AUTOSAR XML (schema 4-0-3)
package /Nexteer/CDD_NvMProxy_swc/ComponentTypes
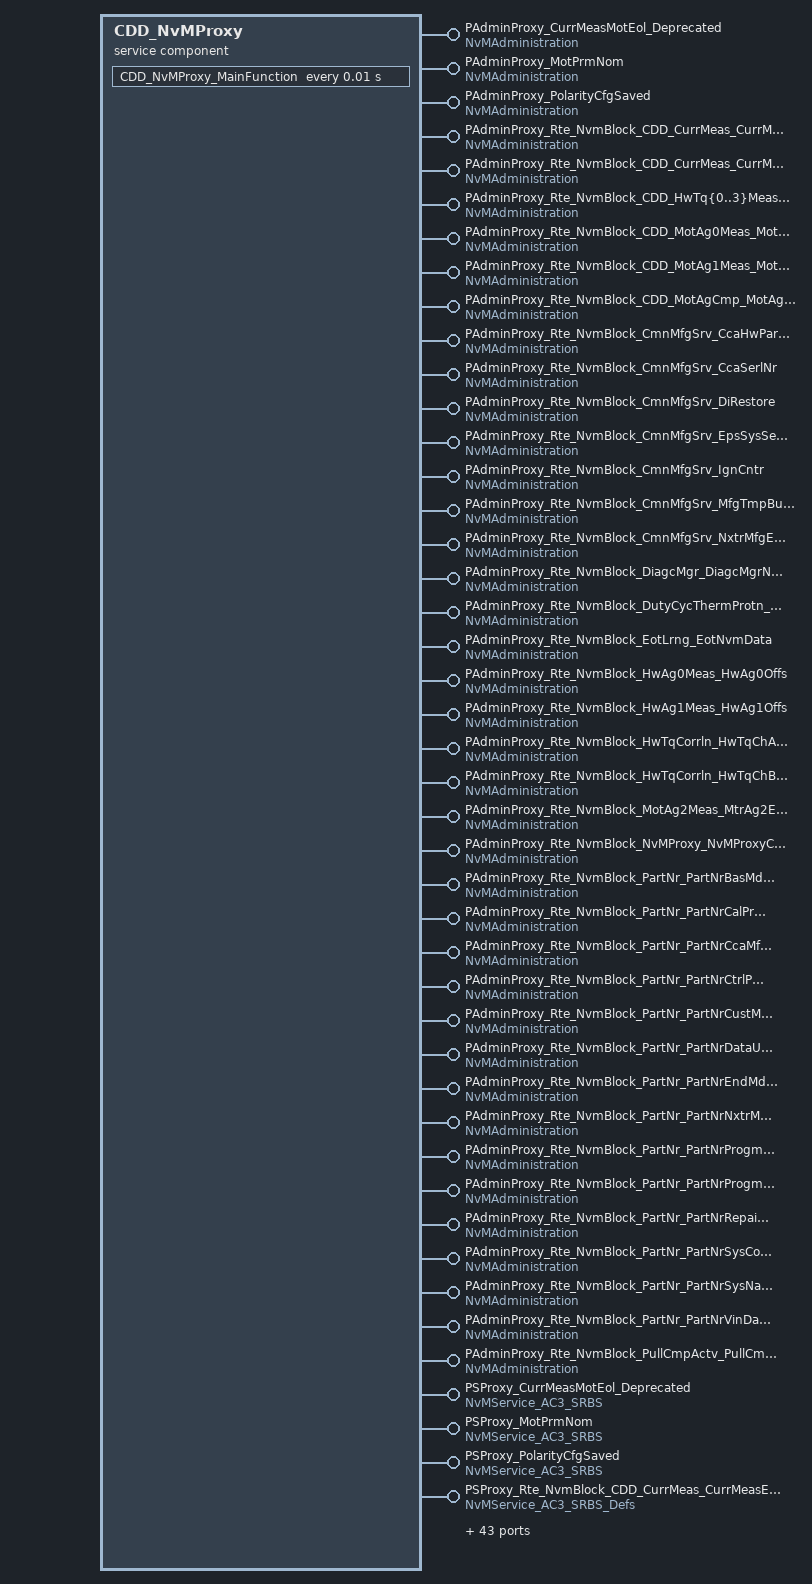
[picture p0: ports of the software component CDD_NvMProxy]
  service sw component type CDD_NvMProxy
    94 x provide port:
      PAdminProxy_CurrMeasMotEol_Deprecated: server-com-spec{operation=SetBlockProtection, queue-length=1}, provided-interface=NvMAdministration
      PAdminProxy_MotPrmNom: server-com-spec{operation=SetBlockProtection, queue-length=1}, provided-interface=NvMAdministration
      PAdminProxy_PolarityCfgSaved: server-com-spec{operation=SetBlockProtection, queue-length=1}, provided-interface=NvMAdministration
      PAdminProxy_Rte_NvmBlock_CDD_CurrMeas_CurrMeasEolGainCalSet: server-com-spec{operation=SetBlockProtection, queue-length=1}, provided-interface=NvMAdministration
      PAdminProxy_Rte_NvmBlock_CDD_CurrMeas_CurrMeasEolOffsCalSet: server-com-spec{operation=SetBlockProtection, queue-length=1}, provided-interface=NvMAdministration
      PAdminProxy_Rte_NvmBlock_CDD_HwTq{0..3}Meas_HwTq{0..3}Offs: server-com-spec{operation=SetBlockProtection, queue-length=1}, provided-interface=NvMAdministration
      PAdminProxy_Rte_NvmBlock_CDD_MotAg0Meas_MotAg0CoeffTbl: server-com-spec{operation=SetBlockProtection, queue-length=1}, provided-interface=NvMAdministration
      PAdminProxy_Rte_NvmBlock_CDD_MotAg1Meas_MotAg1CoeffTbl: server-com-spec{operation=SetBlockProtection, queue-length=1}, provided-interface=NvMAdministration
      PAdminProxy_Rte_NvmBlock_CDD_MotAgCmp_MotAgCmpMotAgBackEmf: server-com-spec{operation=SetBlockProtection, queue-length=1}, provided-interface=NvMAdministration
      PAdminProxy_Rte_NvmBlock_CmnMfgSrv_CcaHwPartNr: server-com-spec{operation=SetBlockProtection, queue-length=1}, provided-interface=NvMAdministration
      PAdminProxy_Rte_NvmBlock_CmnMfgSrv_CcaSerlNr: server-com-spec{operation=SetBlockProtection, queue-length=1}, provided-interface=NvMAdministration
      PAdminProxy_Rte_NvmBlock_CmnMfgSrv_DiRestore: server-com-spec{operation=SetBlockProtection, queue-length=1}, provided-interface=NvMAdministration
      PAdminProxy_Rte_NvmBlock_CmnMfgSrv_EpsSysSerlNr: server-com-spec{operation=SetBlockProtection, queue-length=1}, provided-interface=NvMAdministration
      PAdminProxy_Rte_NvmBlock_CmnMfgSrv_IgnCntr: server-com-spec{operation=SetBlockProtection, queue-length=1}, provided-interface=NvMAdministration
      PAdminProxy_Rte_NvmBlock_CmnMfgSrv_MfgTmpBuf{0..4}: server-com-spec{operation=SetBlockProtection, queue-length=1}, provided-interface=NvMAdministration
      PAdminProxy_Rte_NvmBlock_CmnMfgSrv_NxtrMfgEnaCntr: server-com-spec{operation=SetBlockProtection, queue-length=1}, provided-interface=NvMAdministration
      PAdminProxy_Rte_NvmBlock_DiagcMgr_DiagcMgrNtcFltAry: server-com-spec{operation=SetBlockProtection, queue-length=1}, provided-interface=NvMAdministration
      PAdminProxy_Rte_NvmBlock_DutyCycThermProtn_FilStVal: server-com-spec{operation=SetBlockProtection, queue-length=1}, provided-interface=NvMAdministration
      PAdminProxy_Rte_NvmBlock_EotLrng_EotNvmData: server-com-spec{operation=SetBlockProtection, queue-length=1}, provided-interface=NvMAdministration
      PAdminProxy_Rte_NvmBlock_HwAg0Meas_HwAg0Offs: server-com-spec{operation=SetBlockProtection, queue-length=1}, provided-interface=NvMAdministration
      PAdminProxy_Rte_NvmBlock_HwAg1Meas_HwAg1Offs: server-com-spec{operation=SetBlockProtection, queue-length=1}, provided-interface=NvMAdministration
      PAdminProxy_Rte_NvmBlock_HwTqCorrln_HwTqChACmnModCmpLpFilSt: server-com-spec{operation=SetBlockProtection, queue-length=1}, provided-interface=NvMAdministration
      PAdminProxy_Rte_NvmBlock_HwTqCorrln_HwTqChBCmnModCmpLpFilSt: server-com-spec{operation=SetBlockProtection, queue-length=1}, provided-interface=NvMAdministration
      PAdminProxy_Rte_NvmBlock_MotAg2Meas_MtrAg2EolPrm: server-com-spec{operation=SetBlockProtection, queue-length=1}, provided-interface=NvMAdministration
      PAdminProxy_Rte_NvmBlock_NvMProxy_NvMProxyClsChkBlk: server-com-spec{operation=SetBlockProtection, queue-length=1}, provided-interface=NvMAdministration
      PAdminProxy_Rte_NvmBlock_PartNr_PartNrBasMdlPartNr: server-com-spec{operation=SetBlockProtection, queue-length=1}, provided-interface=NvMAdministration
      PAdminProxy_Rte_NvmBlock_PartNr_PartNrCalProgdSts: server-com-spec{operation=SetBlockProtection, queue-length=1}, provided-interface=NvMAdministration
      PAdminProxy_Rte_NvmBlock_PartNr_PartNrCcaMfgTrakg: server-com-spec{operation=SetBlockProtection, queue-length=1}, provided-interface=NvMAdministration
      PAdminProxy_Rte_NvmBlock_PartNr_PartNrCtrlPidSeedKey: server-com-spec{operation=SetBlockProtection, queue-length=1}, provided-interface=NvMAdministration
      PAdminProxy_Rte_NvmBlock_PartNr_PartNrCustMfgEnaCntr: server-com-spec{operation=SetBlockProtection, queue-length=1}, provided-interface=NvMAdministration
      PAdminProxy_Rte_NvmBlock_PartNr_PartNrDataUniversalNrSysId: server-com-spec{operation=SetBlockProtection, queue-length=1}, provided-interface=NvMAdministration
      PAdminProxy_Rte_NvmBlock_PartNr_PartNrEndMdlPartNr: server-com-spec{operation=SetBlockProtection, queue-length=1}, provided-interface=NvMAdministration
      PAdminProxy_Rte_NvmBlock_PartNr_PartNrNxtrMfgTrakg: server-com-spec{operation=SetBlockProtection, queue-length=1}, provided-interface=NvMAdministration
      PAdminProxy_Rte_NvmBlock_PartNr_PartNrProgmDate: server-com-spec{operation=SetBlockProtection, queue-length=1}, provided-interface=NvMAdministration
      PAdminProxy_Rte_NvmBlock_PartNr_PartNrProgmSessionSeedKey: server-com-spec{operation=SetBlockProtection, queue-length=1}, provided-interface=NvMAdministration
      PAdminProxy_Rte_NvmBlock_PartNr_PartNrRepairShopCod: server-com-spec{operation=SetBlockProtection, queue-length=1}, provided-interface=NvMAdministration
      PAdminProxy_Rte_NvmBlock_PartNr_PartNrSysCodVersNr: server-com-spec{operation=SetBlockProtection, queue-length=1}, provided-interface=NvMAdministration
      PAdminProxy_Rte_NvmBlock_PartNr_PartNrSysName: server-com-spec{operation=SetBlockProtection, queue-length=1}, provided-interface=NvMAdministration
      PAdminProxy_Rte_NvmBlock_PartNr_PartNrVinData: server-com-spec{operation=SetBlockProtection, queue-length=1}, provided-interface=NvMAdministration
      PAdminProxy_Rte_NvmBlock_PullCmpActv_PullCmpLongTerm: server-com-spec{operation=SetBlockProtection, queue-length=1}, provided-interface=NvMAdministration
      PSProxy_CurrMeasMotEol_Deprecated: provided-interface=NvMService_AC3_SRBS
        provided-com-specs:
          operation=EraseBlock, queue-length=1
          operation=GetErrorStatus, queue-length=1
          operation=InvalidateNvBlock, queue-length=1
          operation=ReadBlock, queue-length=1
          operation=SetRamBlockStatus, queue-length=1
          operation=WriteBlock, queue-length=1
      PSProxy_MotPrmNom: provided-interface=NvMService_AC3_SRBS
        provided-com-specs:
          operation=EraseBlock, queue-length=1
          operation=GetErrorStatus, queue-length=1
          operation=InvalidateNvBlock, queue-length=1
          operation=ReadBlock, queue-length=1
          operation=SetRamBlockStatus, queue-length=1
          operation=WriteBlock, queue-length=1
      PSProxy_PolarityCfgSaved: provided-interface=NvMService_AC3_SRBS
        provided-com-specs:
          operation=EraseBlock, queue-length=1
          operation=GetErrorStatus, queue-length=1
          operation=InvalidateNvBlock, queue-length=1
          operation=ReadBlock, queue-length=1
          operation=SetRamBlockStatus, queue-length=1
          operation=WriteBlock, queue-length=1
      PSProxy_Rte_NvmBlock_CDD_CurrMeas_CurrMeasEolGainCalSet: provided-interface=NvMService_AC3_SRBS_Defs
        provided-com-specs:
          operation=EraseBlock, queue-length=1
          operation=GetErrorStatus, queue-length=1
          operation=InvalidateNvBlock, queue-length=1
          operation=ReadBlock, queue-length=1
          operation=RestoreBlockDefaults, queue-length=1
          operation=SetRamBlockStatus, queue-length=1
          operation=WriteBlock, queue-length=1
      PSProxy_Rte_NvmBlock_CDD_CurrMeas_CurrMeasEolOffsCalSet: provided-interface=NvMService_AC3_SRBS_Defs
        provided-com-specs:
          operation=EraseBlock, queue-length=1
          operation=GetErrorStatus, queue-length=1
          operation=InvalidateNvBlock, queue-length=1
          operation=ReadBlock, queue-length=1
          operation=RestoreBlockDefaults, queue-length=1
          operation=SetRamBlockStatus, queue-length=1
          operation=WriteBlock, queue-length=1
      PSProxy_Rte_NvmBlock_CDD_HwTq0Meas_HwTq0Offs: provided-interface=NvMService_AC3_SRBS_Defs
        provided-com-specs:
          operation=EraseBlock, queue-length=1
          operation=GetErrorStatus, queue-length=1
          operation=InvalidateNvBlock, queue-length=1
          operation=ReadBlock, queue-length=1
          operation=RestoreBlockDefaults, queue-length=1
          operation=SetRamBlockStatus, queue-length=1
          operation=WriteBlock, queue-length=1
      PSProxy_Rte_NvmBlock_CDD_HwTq1Meas_HwTq1Offs: provided-interface=NvMService_AC3_SRBS_Defs
        provided-com-specs:
          operation=EraseBlock, queue-length=1
          operation=GetErrorStatus, queue-length=1
          operation=InvalidateNvBlock, queue-length=1
          operation=ReadBlock, queue-length=1
          operation=RestoreBlockDefaults, queue-length=1
          operation=SetRamBlockStatus, queue-length=1
          operation=WriteBlock, queue-length=1
      PSProxy_Rte_NvmBlock_CDD_HwTq2Meas_HwTq2Offs: provided-interface=NvMService_AC3_SRBS_Defs
        provided-com-specs:
          operation=EraseBlock, queue-length=1
          operation=GetErrorStatus, queue-length=1
          operation=InvalidateNvBlock, queue-length=1
          operation=ReadBlock, queue-length=1
          operation=RestoreBlockDefaults, queue-length=1
          operation=SetRamBlockStatus, queue-length=1
          operation=WriteBlock, queue-length=1
      PSProxy_Rte_NvmBlock_CDD_HwTq3Meas_HwTq3Offs: provided-interface=NvMService_AC3_SRBS_Defs
        provided-com-specs:
          operation=EraseBlock, queue-length=1
          operation=GetErrorStatus, queue-length=1
          operation=InvalidateNvBlock, queue-length=1
          operation=ReadBlock, queue-length=1
          operation=RestoreBlockDefaults, queue-length=1
          operation=SetRamBlockStatus, queue-length=1
          operation=WriteBlock, queue-length=1
      PSProxy_Rte_NvmBlock_CDD_MotAg0Meas_MotAg0CoeffTbl: provided-interface=NvMService_AC3_SRBS_Defs
        provided-com-specs:
          operation=EraseBlock, queue-length=1
          operation=GetErrorStatus, queue-length=1
          operation=InvalidateNvBlock, queue-length=1
          operation=ReadBlock, queue-length=1
          operation=RestoreBlockDefaults, queue-length=1
          operation=SetRamBlockStatus, queue-length=1
          operation=WriteBlock, queue-length=1
      PSProxy_Rte_NvmBlock_CDD_MotAg1Meas_MotAg1CoeffTbl: provided-interface=NvMService_AC3_SRBS_Defs
        provided-com-specs:
          operation=EraseBlock, queue-length=1
          operation=GetErrorStatus, queue-length=1
          operation=InvalidateNvBlock, queue-length=1
          operation=ReadBlock, queue-length=1
          operation=RestoreBlockDefaults, queue-length=1
          operation=SetRamBlockStatus, queue-length=1
          operation=WriteBlock, queue-length=1
      PSProxy_Rte_NvmBlock_CDD_MotAgCmp_MotAgCmpMotAgBackEmf: provided-interface=NvMService_AC3_SRBS_Defs
        provided-com-specs:
          operation=EraseBlock, queue-length=1
          operation=GetErrorStatus, queue-length=1
          operation=InvalidateNvBlock, queue-length=1
          operation=ReadBlock, queue-length=1
          operation=RestoreBlockDefaults, queue-length=1
          operation=SetRamBlockStatus, queue-length=1
          operation=WriteBlock, queue-length=1
      PSProxy_Rte_NvmBlock_CmnMfgSrv_CcaHwPartNr: provided-interface=NvMService_AC3_SRBS
        provided-com-specs:
          operation=EraseBlock, queue-length=1
          operation=GetErrorStatus, queue-length=1
          operation=InvalidateNvBlock, queue-length=1
          operation=ReadBlock, queue-length=1
          operation=SetRamBlockStatus, queue-length=1
          operation=WriteBlock, queue-length=1
      PSProxy_Rte_NvmBlock_CmnMfgSrv_CcaSerlNr: provided-interface=NvMService_AC3_SRBS
        provided-com-specs:
          operation=EraseBlock, queue-length=1
          operation=GetErrorStatus, queue-length=1
          operation=InvalidateNvBlock, queue-length=1
          operation=ReadBlock, queue-length=1
          operation=SetRamBlockStatus, queue-length=1
          operation=WriteBlock, queue-length=1
      PSProxy_Rte_NvmBlock_CmnMfgSrv_DiRestore: provided-interface=NvMService_AC3_SRBS
        provided-com-specs:
          operation=EraseBlock, queue-length=1
          operation=GetErrorStatus, queue-length=1
          operation=InvalidateNvBlock, queue-length=1
          operation=ReadBlock, queue-length=1
          operation=SetRamBlockStatus, queue-length=1
          operation=WriteBlock, queue-length=1
      PSProxy_Rte_NvmBlock_CmnMfgSrv_EpsSysSerlNr: provided-interface=NvMService_AC3_SRBS
        provided-com-specs:
          operation=EraseBlock, queue-length=1
          operation=GetErrorStatus, queue-length=1
          operation=InvalidateNvBlock, queue-length=1
          operation=ReadBlock, queue-length=1
          operation=SetRamBlockStatus, queue-length=1
          operation=WriteBlock, queue-length=1
      PSProxy_Rte_NvmBlock_CmnMfgSrv_IgnCntr: provided-interface=NvMService_AC3_SRBS_Defs
        provided-com-specs:
          operation=EraseBlock, queue-length=1
          operation=GetErrorStatus, queue-length=1
          operation=InvalidateNvBlock, queue-length=1
          operation=ReadBlock, queue-length=1
          operation=RestoreBlockDefaults, queue-length=1
          operation=SetRamBlockStatus, queue-length=1
          operation=WriteBlock, queue-length=1
      PSProxy_Rte_NvmBlock_CmnMfgSrv_MfgTmpBuf0: provided-interface=NvMService_AC3_SRBS
        provided-com-specs:
          operation=EraseBlock, queue-length=1
          operation=GetErrorStatus, queue-length=1
          operation=InvalidateNvBlock, queue-length=1
          operation=ReadBlock, queue-length=1
          operation=SetRamBlockStatus, queue-length=1
          operation=WriteBlock, queue-length=1
      PSProxy_Rte_NvmBlock_CmnMfgSrv_MfgTmpBuf1: provided-interface=NvMService_AC3_SRBS
        provided-com-specs:
          operation=EraseBlock, queue-length=1
          operation=GetErrorStatus, queue-length=1
          operation=InvalidateNvBlock, queue-length=1
          operation=ReadBlock, queue-length=1
          operation=SetRamBlockStatus, queue-length=1
          operation=WriteBlock, queue-length=1
      PSProxy_Rte_NvmBlock_CmnMfgSrv_MfgTmpBuf2: provided-interface=NvMService_AC3_SRBS
        provided-com-specs:
          operation=EraseBlock, queue-length=1
          operation=GetErrorStatus, queue-length=1
          operation=InvalidateNvBlock, queue-length=1
          operation=ReadBlock, queue-length=1
          operation=SetRamBlockStatus, queue-length=1
          operation=WriteBlock, queue-length=1
      PSProxy_Rte_NvmBlock_CmnMfgSrv_MfgTmpBuf3: provided-interface=NvMService_AC3_SRBS
        provided-com-specs:
          operation=EraseBlock, queue-length=1
          operation=GetErrorStatus, queue-length=1
          operation=InvalidateNvBlock, queue-length=1
          operation=ReadBlock, queue-length=1
          operation=SetRamBlockStatus, queue-length=1
          operation=WriteBlock, queue-length=1
      PSProxy_Rte_NvmBlock_CmnMfgSrv_MfgTmpBuf4: provided-interface=NvMService_AC3_SRBS
        provided-com-specs:
          operation=EraseBlock, queue-length=1
          operation=GetErrorStatus, queue-length=1
          operation=InvalidateNvBlock, queue-length=1
          operation=ReadBlock, queue-length=1
          operation=SetRamBlockStatus, queue-length=1
          operation=WriteBlock, queue-length=1
      PSProxy_Rte_NvmBlock_CmnMfgSrv_NxtrMfgEnaCntr: provided-interface=NvMService_AC3_SRBS_Defs
        provided-com-specs:
          operation=EraseBlock, queue-length=1
          operation=GetErrorStatus, queue-length=1
          operation=InvalidateNvBlock, queue-length=1
          operation=ReadBlock, queue-length=1
          operation=RestoreBlockDefaults, queue-length=1
          operation=SetRamBlockStatus, queue-length=1
          operation=WriteBlock, queue-length=1
      PSProxy_Rte_NvmBlock_DiagcMgr_DiagcMgrNtcFltAry: provided-interface=NvMService_AC3_SRBS
        provided-com-specs:
          operation=EraseBlock, queue-length=1
          operation=GetErrorStatus, queue-length=1
          operation=InvalidateNvBlock, queue-length=1
          operation=ReadBlock, queue-length=1
          operation=SetRamBlockStatus, queue-length=1
          operation=WriteBlock, queue-length=1
      PSProxy_Rte_NvmBlock_DutyCycThermProtn_FilStVal: provided-interface=NvMService_AC3_SRBS_Defs
        provided-com-specs:
          operation=EraseBlock, queue-length=1
          operation=GetErrorStatus, queue-length=1
          operation=InvalidateNvBlock, queue-length=1
          operation=ReadBlock, queue-length=1
          operation=RestoreBlockDefaults, queue-length=1
          operation=SetRamBlockStatus, queue-length=1
          operation=WriteBlock, queue-length=1
      PSProxy_Rte_NvmBlock_EotLrng_EotNvmData: provided-interface=NvMService_AC3_SRBS_Defs
        provided-com-specs:
          operation=EraseBlock, queue-length=1
          operation=GetErrorStatus, queue-length=1
          operation=InvalidateNvBlock, queue-length=1
          operation=ReadBlock, queue-length=1
          operation=RestoreBlockDefaults, queue-length=1
          operation=SetRamBlockStatus, queue-length=1
          operation=WriteBlock, queue-length=1
      PSProxy_Rte_NvmBlock_HwAg0Meas_HwAg0Offs: provided-interface=NvMService_AC3_SRBS_Defs
        provided-com-specs:
          operation=EraseBlock, queue-length=1
          operation=GetErrorStatus, queue-length=1
          operation=InvalidateNvBlock, queue-length=1
          operation=ReadBlock, queue-length=1
          operation=RestoreBlockDefaults, queue-length=1
          operation=SetRamBlockStatus, queue-length=1
          operation=WriteBlock, queue-length=1
      PSProxy_Rte_NvmBlock_HwAg1Meas_HwAg1Offs: provided-interface=NvMService_AC3_SRBS_Defs
        provided-com-specs:
          operation=EraseBlock, queue-length=1
          operation=GetErrorStatus, queue-length=1
          operation=InvalidateNvBlock, queue-length=1
          operation=ReadBlock, queue-length=1
          operation=RestoreBlockDefaults, queue-length=1
          operation=SetRamBlockStatus, queue-length=1
          operation=WriteBlock, queue-length=1
      PSProxy_Rte_NvmBlock_HwTqCorrln_HwTqChACmnModCmpLpFilSt: provided-interface=NvMService_AC3_SRBS_Defs
        provided-com-specs:
          operation=EraseBlock, queue-length=1
          operation=GetErrorStatus, queue-length=1
          operation=InvalidateNvBlock, queue-length=1
          operation=ReadBlock, queue-length=1
          operation=RestoreBlockDefaults, queue-length=1
          operation=SetRamBlockStatus, queue-length=1
          operation=WriteBlock, queue-length=1
      PSProxy_Rte_NvmBlock_HwTqCorrln_HwTqChBCmnModCmpLpFilSt: provided-interface=NvMService_AC3_SRBS_Defs
        provided-com-specs:
          operation=EraseBlock, queue-length=1
          operation=GetErrorStatus, queue-length=1
          operation=InvalidateNvBlock, queue-length=1
          operation=ReadBlock, queue-length=1
          operation=RestoreBlockDefaults, queue-length=1
          operation=SetRamBlockStatus, queue-length=1
          operation=WriteBlock, queue-length=1
      PSProxy_Rte_NvmBlock_MotAg2Meas_MtrAg2EolPrm: provided-interface=NvMService_AC3_SRBS_Defs
        provided-com-specs:
          operation=EraseBlock, queue-length=1
          operation=GetErrorStatus, queue-length=1
          operation=InvalidateNvBlock, queue-length=1
          operation=ReadBlock, queue-length=1
          operation=RestoreBlockDefaults, queue-length=1
          operation=SetRamBlockStatus, queue-length=1
          operation=WriteBlock, queue-length=1
      PSProxy_Rte_NvmBlock_NvMProxy_NvMProxyClsChkBlk: provided-interface=NvMService_AC3_SRBS
        provided-com-specs:
          operation=EraseBlock, queue-length=1
          operation=GetErrorStatus, queue-length=1
          operation=InvalidateNvBlock, queue-length=1
          operation=ReadBlock, queue-length=1
          operation=SetRamBlockStatus, queue-length=1
          operation=WriteBlock, queue-length=1
      PSProxy_Rte_NvmBlock_PartNr_PartNrBasMdlPartNr: provided-interface=NvMService_AC3_SRBS_Defs
        provided-com-specs:
          operation=EraseBlock, queue-length=1
          operation=GetErrorStatus, queue-length=1
          operation=InvalidateNvBlock, queue-length=1
          operation=ReadBlock, queue-length=1
          operation=RestoreBlockDefaults, queue-length=1
          operation=SetRamBlockStatus, queue-length=1
          operation=WriteBlock, queue-length=1
      PSProxy_Rte_NvmBlock_PartNr_PartNrCalProgdSts: provided-interface=NvMService_AC3_SRBS_Defs
        provided-com-specs:
          operation=EraseBlock, queue-length=1
          operation=GetErrorStatus, queue-length=1
          operation=InvalidateNvBlock, queue-length=1
          operation=ReadBlock, queue-length=1
          operation=RestoreBlockDefaults, queue-length=1
          operation=SetRamBlockStatus, queue-length=1
          operation=WriteBlock, queue-length=1
      PSProxy_Rte_NvmBlock_PartNr_PartNrCcaMfgTrakg: provided-interface=NvMService_AC3_SRBS_Defs
        provided-com-specs:
          operation=EraseBlock, queue-length=1
          operation=GetErrorStatus, queue-length=1
          operation=InvalidateNvBlock, queue-length=1
          operation=ReadBlock, queue-length=1
          operation=RestoreBlockDefaults, queue-length=1
          operation=SetRamBlockStatus, queue-length=1
          operation=WriteBlock, queue-length=1
      PSProxy_Rte_NvmBlock_PartNr_PartNrCtrlPidSeedKey: provided-interface=NvMService_AC3_SRBS_Defs
        provided-com-specs:
          operation=EraseBlock, queue-length=1
          operation=GetErrorStatus, queue-length=1
          operation=InvalidateNvBlock, queue-length=1
          operation=ReadBlock, queue-length=1
          operation=RestoreBlockDefaults, queue-length=1
          operation=SetRamBlockStatus, queue-length=1
          operation=WriteBlock, queue-length=1
      PSProxy_Rte_NvmBlock_PartNr_PartNrCustMfgEnaCntr: provided-interface=NvMService_AC3_SRBS_Defs
        provided-com-specs:
          operation=EraseBlock, queue-length=1
          operation=GetErrorStatus, queue-length=1
          operation=InvalidateNvBlock, queue-length=1
          operation=ReadBlock, queue-length=1
          operation=RestoreBlockDefaults, queue-length=1
          operation=SetRamBlockStatus, queue-length=1
          operation=WriteBlock, queue-length=1
      PSProxy_Rte_NvmBlock_PartNr_PartNrDataUniversalNrSysId: provided-interface=NvMService_AC3_SRBS_Defs
        provided-com-specs:
          operation=EraseBlock, queue-length=1
          operation=GetErrorStatus, queue-length=1
          operation=InvalidateNvBlock, queue-length=1
          operation=ReadBlock, queue-length=1
          operation=RestoreBlockDefaults, queue-length=1
          operation=SetRamBlockStatus, queue-length=1
          operation=WriteBlock, queue-length=1
      PSProxy_Rte_NvmBlock_PartNr_PartNrEndMdlPartNr: provided-interface=NvMService_AC3_SRBS_Defs
        provided-com-specs:
          operation=EraseBlock, queue-length=1
          operation=GetErrorStatus, queue-length=1
          operation=InvalidateNvBlock, queue-length=1
          operation=ReadBlock, queue-length=1
          operation=RestoreBlockDefaults, queue-length=1
          operation=SetRamBlockStatus, queue-length=1
          operation=WriteBlock, queue-length=1
      PSProxy_Rte_NvmBlock_PartNr_PartNrNxtrMfgTrakg: provided-interface=NvMService_AC3_SRBS_Defs
        provided-com-specs:
          operation=EraseBlock, queue-length=1
          operation=GetErrorStatus, queue-length=1
          operation=InvalidateNvBlock, queue-length=1
          operation=ReadBlock, queue-length=1
          operation=RestoreBlockDefaults, queue-length=1
          operation=SetRamBlockStatus, queue-length=1
          operation=WriteBlock, queue-length=1
      PSProxy_Rte_NvmBlock_PartNr_PartNrProgmDate: provided-interface=NvMService_AC3_SRBS_Defs
        provided-com-specs:
          operation=EraseBlock, queue-length=1
          operation=GetErrorStatus, queue-length=1
          operation=InvalidateNvBlock, queue-length=1
          operation=ReadBlock, queue-length=1
          operation=RestoreBlockDefaults, queue-length=1
          operation=SetRamBlockStatus, queue-length=1
          operation=WriteBlock, queue-length=1
      PSProxy_Rte_NvmBlock_PartNr_PartNrProgmSessionSeedKey: provided-interface=NvMService_AC3_SRBS_Defs
        provided-com-specs:
          operation=EraseBlock, queue-length=1
          operation=GetErrorStatus, queue-length=1
          operation=InvalidateNvBlock, queue-length=1
          operation=ReadBlock, queue-length=1
          operation=RestoreBlockDefaults, queue-length=1
          operation=SetRamBlockStatus, queue-length=1
          operation=WriteBlock, queue-length=1
      PSProxy_Rte_NvmBlock_PartNr_PartNrRepairShopCod: provided-interface=NvMService_AC3_SRBS_Defs
        provided-com-specs:
          operation=EraseBlock, queue-length=1
          operation=GetErrorStatus, queue-length=1
          operation=InvalidateNvBlock, queue-length=1
          operation=ReadBlock, queue-length=1
          operation=RestoreBlockDefaults, queue-length=1
          operation=SetRamBlockStatus, queue-length=1
          operation=WriteBlock, queue-length=1
      PSProxy_Rte_NvmBlock_PartNr_PartNrSysCodVersNr: provided-interface=NvMService_AC3_SRBS_Defs
        provided-com-specs:
          operation=EraseBlock, queue-length=1
          operation=GetErrorStatus, queue-length=1
          operation=InvalidateNvBlock, queue-length=1
          operation=ReadBlock, queue-length=1
          operation=RestoreBlockDefaults, queue-length=1
          operation=SetRamBlockStatus, queue-length=1
          operation=WriteBlock, queue-length=1
      PSProxy_Rte_NvmBlock_PartNr_PartNrSysName: provided-interface=NvMService_AC3_SRBS_Defs
        provided-com-specs:
          operation=EraseBlock, queue-length=1
          operation=GetErrorStatus, queue-length=1
          operation=InvalidateNvBlock, queue-length=1
          operation=ReadBlock, queue-length=1
          operation=RestoreBlockDefaults, queue-length=1
          operation=SetRamBlockStatus, queue-length=1
          operation=WriteBlock, queue-length=1
      PSProxy_Rte_NvmBlock_PartNr_PartNrVinData: provided-interface=NvMService_AC3_SRBS_Defs
        provided-com-specs:
          operation=EraseBlock, queue-length=1
          operation=GetErrorStatus, queue-length=1
          operation=InvalidateNvBlock, queue-length=1
          operation=ReadBlock, queue-length=1
          operation=RestoreBlockDefaults, queue-length=1
          operation=SetRamBlockStatus, queue-length=1
          operation=WriteBlock, queue-length=1
      PSProxy_Rte_NvmBlock_PullCmpActv_PullCmpLongTerm: provided-interface=NvMService_AC3_SRBS_Defs
        provided-com-specs:
          operation=EraseBlock, queue-length=1
          operation=GetErrorStatus, queue-length=1
          operation=InvalidateNvBlock, queue-length=1
          operation=ReadBlock, queue-length=1
          operation=RestoreBlockDefaults, queue-length=1
          operation=SetRamBlockStatus, queue-length=1
          operation=WriteBlock, queue-length=1
    behavior CDD_NvMProxyInternalBehavior
      141 x operation invoked event:
        OIT_EraseBlock_PSProxy_CurrMeasMotEol_Deprecated_EraseBlock: start-on-event=EraseBlock, operation=PSProxy_CurrMeasMotEol_Deprecated.EraseBlock
        OIT_EraseBlock_PSProxy_MotPrmNom_EraseBlock: start-on-event=EraseBlock, operation=PSProxy_MotPrmNom.EraseBlock
        OIT_EraseBlock_PSProxy_PolarityCfgSaved_EraseBlock: start-on-event=EraseBlock, operation=PSProxy_PolarityCfgSaved.EraseBlock
        OIT_EraseBlock_PSProxy_Rte_NvmBlock_CDD_CurrMeas_CurrMeasEolGainCalSet_EraseBlock: start-on-event=EraseBlock, operation=PSProxy_Rte_NvmBlock_CDD_CurrMeas_CurrMeasEolGainCalSet.EraseBlock
        OIT_EraseBlock_PSProxy_Rte_NvmBlock_CDD_CurrMeas_CurrMeasEolOffsCalSet_EraseBlock: start-on-event=EraseBlock, operation=PSProxy_Rte_NvmBlock_CDD_CurrMeas_CurrMeasEolOffsCalSet.EraseBlock
        OIT_EraseBlock_PSProxy_Rte_NvmBlock_CDD_HwTq{0..3}Meas_HwTq{0..3}Offs_EraseBlock: start-on-event=EraseBlock, operation=PSProxy_Rte_NvmBlock_CDD_HwTq{0..3}Meas_HwTq{0..3}Offs.EraseBlock
        OIT_EraseBlock_PSProxy_Rte_NvmBlock_CDD_MotAg0Meas_MotAg0CoeffTbl_EraseBlock: start-on-event=EraseBlock, operation=PSProxy_Rte_NvmBlock_CDD_MotAg0Meas_MotAg0CoeffTbl.EraseBlock
        OIT_EraseBlock_PSProxy_Rte_NvmBlock_CDD_MotAg1Meas_MotAg1CoeffTbl_EraseBlock: start-on-event=EraseBlock, operation=PSProxy_Rte_NvmBlock_CDD_MotAg1Meas_MotAg1CoeffTbl.EraseBlock
        OIT_EraseBlock_PSProxy_Rte_NvmBlock_CDD_MotAgCmp_MotAgCmpMotAgBackEmf_EraseBlock: start-on-event=EraseBlock, operation=PSProxy_Rte_NvmBlock_CDD_MotAgCmp_MotAgCmpMotAgBackEmf.EraseBlock
        OIT_EraseBlock_PSProxy_Rte_NvmBlock_CmnMfgSrv_CcaHwPartNr_EraseBlock: start-on-event=EraseBlock, operation=PSProxy_Rte_NvmBlock_CmnMfgSrv_CcaHwPartNr.EraseBlock
        OIT_EraseBlock_PSProxy_Rte_NvmBlock_CmnMfgSrv_CcaSerlNr_EraseBlock: start-on-event=EraseBlock, operation=PSProxy_Rte_NvmBlock_CmnMfgSrv_CcaSerlNr.EraseBlock
        OIT_EraseBlock_PSProxy_Rte_NvmBlock_CmnMfgSrv_DiRestore_EraseBlock: start-on-event=EraseBlock, operation=PSProxy_Rte_NvmBlock_CmnMfgSrv_DiRestore.EraseBlock
        OIT_EraseBlock_PSProxy_Rte_NvmBlock_CmnMfgSrv_EpsSysSerlNr_EraseBlock: start-on-event=EraseBlock, operation=PSProxy_Rte_NvmBlock_CmnMfgSrv_EpsSysSerlNr.EraseBlock
        OIT_EraseBlock_PSProxy_Rte_NvmBlock_CmnMfgSrv_IgnCntr_EraseBlock: start-on-event=EraseBlock, operation=PSProxy_Rte_NvmBlock_CmnMfgSrv_IgnCntr.EraseBlock
        OIT_EraseBlock_PSProxy_Rte_NvmBlock_CmnMfgSrv_MfgTmpBuf{0..4}_EraseBlock: start-on-event=EraseBlock, operation=PSProxy_Rte_NvmBlock_CmnMfgSrv_MfgTmpBuf{0..4}.EraseBlock
        OIT_EraseBlock_PSProxy_Rte_NvmBlock_CmnMfgSrv_NxtrMfgEnaCntr_EraseBlock: start-on-event=EraseBlock, operation=PSProxy_Rte_NvmBlock_CmnMfgSrv_NxtrMfgEnaCntr.EraseBlock
        OIT_EraseBlock_PSProxy_Rte_NvmBlock_DiagcMgr_DiagcMgrNtcFltAry_EraseBlock: start-on-event=EraseBlock, operation=PSProxy_Rte_NvmBlock_DiagcMgr_DiagcMgrNtcFltAry.EraseBlock
        OIT_EraseBlock_PSProxy_Rte_NvmBlock_DutyCycThermProtn_FilStVal_EraseBlock: start-on-event=EraseBlock, operation=PSProxy_Rte_NvmBlock_DutyCycThermProtn_FilStVal.EraseBlock
        OIT_EraseBlock_PSProxy_Rte_NvmBlock_EotLrng_EotNvmData_EraseBlock: start-on-event=EraseBlock, operation=PSProxy_Rte_NvmBlock_EotLrng_EotNvmData.EraseBlock
        OIT_EraseBlock_PSProxy_Rte_NvmBlock_HwAg0Meas_HwAg0Offs_EraseBlock: start-on-event=EraseBlock, operation=PSProxy_Rte_NvmBlock_HwAg0Meas_HwAg0Offs.EraseBlock
        OIT_EraseBlock_PSProxy_Rte_NvmBlock_HwAg1Meas_HwAg1Offs_EraseBlock: start-on-event=EraseBlock, operation=PSProxy_Rte_NvmBlock_HwAg1Meas_HwAg1Offs.EraseBlock
        OIT_EraseBlock_PSProxy_Rte_NvmBlock_HwTqCorrln_HwTqChACmnModCmpLpFilSt_EraseBlock: start-on-event=EraseBlock, operation=PSProxy_Rte_NvmBlock_HwTqCorrln_HwTqChACmnModCmpLpFilSt.EraseBlock
        OIT_EraseBlock_PSProxy_Rte_NvmBlock_HwTqCorrln_HwTqChBCmnModCmpLpFilSt_EraseBlock: start-on-event=EraseBlock, operation=PSProxy_Rte_NvmBlock_HwTqCorrln_HwTqChBCmnModCmpLpFilSt.EraseBlock
        OIT_EraseBlock_PSProxy_Rte_NvmBlock_MotAg2Meas_MtrAg2EolPrm_EraseBlock: start-on-event=EraseBlock, operation=PSProxy_Rte_NvmBlock_MotAg2Meas_MtrAg2EolPrm.EraseBlock
        OIT_EraseBlock_PSProxy_Rte_NvmBlock_NvMProxy_NvMProxyClsChkBlk_EraseBlock: start-on-event=EraseBlock, operation=PSProxy_Rte_NvmBlock_NvMProxy_NvMProxyClsChkBlk.EraseBlock
        OIT_EraseBlock_PSProxy_Rte_NvmBlock_PartNr_PartNrBasMdlPartNr_EraseBlock: start-on-event=EraseBlock, operation=PSProxy_Rte_NvmBlock_PartNr_PartNrBasMdlPartNr.EraseBlock
        OIT_EraseBlock_PSProxy_Rte_NvmBlock_PartNr_PartNrCalProgdSts_EraseBlock: start-on-event=EraseBlock, operation=PSProxy_Rte_NvmBlock_PartNr_PartNrCalProgdSts.EraseBlock
        OIT_EraseBlock_PSProxy_Rte_NvmBlock_PartNr_PartNrCcaMfgTrakg_EraseBlock: start-on-event=EraseBlock, operation=PSProxy_Rte_NvmBlock_PartNr_PartNrCcaMfgTrakg.EraseBlock
        OIT_EraseBlock_PSProxy_Rte_NvmBlock_PartNr_PartNrCtrlPidSeedKey_EraseBlock: start-on-event=EraseBlock, operation=PSProxy_Rte_NvmBlock_PartNr_PartNrCtrlPidSeedKey.EraseBlock
        OIT_EraseBlock_PSProxy_Rte_NvmBlock_PartNr_PartNrCustMfgEnaCntr_EraseBlock: start-on-event=EraseBlock, operation=PSProxy_Rte_NvmBlock_PartNr_PartNrCustMfgEnaCntr.EraseBlock
        OIT_EraseBlock_PSProxy_Rte_NvmBlock_PartNr_PartNrDataUniversalNrSysId_EraseBlock: start-on-event=EraseBlock, operation=PSProxy_Rte_NvmBlock_PartNr_PartNrDataUniversalNrSysId.EraseBlock
        OIT_EraseBlock_PSProxy_Rte_NvmBlock_PartNr_PartNrEndMdlPartNr_EraseBlock: start-on-event=EraseBlock, operation=PSProxy_Rte_NvmBlock_PartNr_PartNrEndMdlPartNr.EraseBlock
        OIT_EraseBlock_PSProxy_Rte_NvmBlock_PartNr_PartNrNxtrMfgTrakg_EraseBlock: start-on-event=EraseBlock, operation=PSProxy_Rte_NvmBlock_PartNr_PartNrNxtrMfgTrakg.EraseBlock
        OIT_EraseBlock_PSProxy_Rte_NvmBlock_PartNr_PartNrProgmDate_EraseBlock: start-on-event=EraseBlock, operation=PSProxy_Rte_NvmBlock_PartNr_PartNrProgmDate.EraseBlock
        OIT_EraseBlock_PSProxy_Rte_NvmBlock_PartNr_PartNrProgmSessionSeedKey_EraseBlock: start-on-event=EraseBlock, operation=PSProxy_Rte_NvmBlock_PartNr_PartNrProgmSessionSeedKey.EraseBlock
        OIT_EraseBlock_PSProxy_Rte_NvmBlock_PartNr_PartNrRepairShopCod_EraseBlock: start-on-event=EraseBlock, operation=PSProxy_Rte_NvmBlock_PartNr_PartNrRepairShopCod.EraseBlock
        OIT_EraseBlock_PSProxy_Rte_NvmBlock_PartNr_PartNrSysCodVersNr_EraseBlock: start-on-event=EraseBlock, operation=PSProxy_Rte_NvmBlock_PartNr_PartNrSysCodVersNr.EraseBlock
        OIT_EraseBlock_PSProxy_Rte_NvmBlock_PartNr_PartNrSysName_EraseBlock: start-on-event=EraseBlock, operation=PSProxy_Rte_NvmBlock_PartNr_PartNrSysName.EraseBlock
        OIT_EraseBlock_PSProxy_Rte_NvmBlock_PartNr_PartNrVinData_EraseBlock: start-on-event=EraseBlock, operation=PSProxy_Rte_NvmBlock_PartNr_PartNrVinData.EraseBlock
        OIT_EraseBlock_PSProxy_Rte_NvmBlock_PullCmpActv_PullCmpLongTerm_EraseBlock: start-on-event=EraseBlock, operation=PSProxy_Rte_NvmBlock_PullCmpActv_PullCmpLongTerm.EraseBlock
        OIT_GetErrorStatus_PSProxy_CurrMeasMotEol_Deprecated_GetErrorStatus: start-on-event=GetErrorStatus, operation=PSProxy_CurrMeasMotEol_Deprecated.GetErrorStatus
        OIT_GetErrorStatus_PSProxy_MotPrmNom_GetErrorStatus: start-on-event=GetErrorStatus, operation=PSProxy_MotPrmNom.GetErrorStatus
        OIT_GetErrorStatus_PSProxy_PolarityCfgSaved_GetErrorStatus: start-on-event=GetErrorStatus, operation=PSProxy_PolarityCfgSaved.GetErrorStatus
        OIT_GetErrorStatus_PSProxy_Rte_NvmBlock_CDD_CurrMeas_CurrMeasEolGainCalSet_GetErrorStatus: start-on-event=GetErrorStatus, operation=PSProxy_Rte_NvmBlock_CDD_CurrMeas_CurrMeasEolGainCalSet.GetErrorStatus
        OIT_GetErrorStatus_PSProxy_Rte_NvmBlock_CDD_CurrMeas_CurrMeasEolOffsCalSet_GetErrorStatus: start-on-event=GetErrorStatus, operation=PSProxy_Rte_NvmBlock_CDD_CurrMeas_CurrMeasEolOffsCalSet.GetErrorStatus
        OIT_GetErrorStatus_PSProxy_Rte_NvmBlock_CDD_HwTq{0..3}Meas_HwTq{0..3}Offs_GetErrorStatus: start-on-event=GetErrorStatus, operation=PSProxy_Rte_NvmBlock_CDD_HwTq{0..3}Meas_HwTq{0..3}Offs.GetErrorStatus
        OIT_GetErrorStatus_PSProxy_Rte_NvmBlock_CDD_MotAg0Meas_MotAg0CoeffTbl_GetErrorStatus: start-on-event=GetErrorStatus, operation=PSProxy_Rte_NvmBlock_CDD_MotAg0Meas_MotAg0CoeffTbl.GetErrorStatus
        OIT_GetErrorStatus_PSProxy_Rte_NvmBlock_CDD_MotAg1Meas_MotAg1CoeffTbl_GetErrorStatus: start-on-event=GetErrorStatus, operation=PSProxy_Rte_NvmBlock_CDD_MotAg1Meas_MotAg1CoeffTbl.GetErrorStatus
        OIT_GetErrorStatus_PSProxy_Rte_NvmBlock_CDD_MotAgCmp_MotAgCmpMotAgBackEmf_GetErrorStatus: start-on-event=GetErrorStatus, operation=PSProxy_Rte_NvmBlock_CDD_MotAgCmp_MotAgCmpMotAgBackEmf.GetErrorStatus
        OIT_GetErrorStatus_PSProxy_Rte_NvmBlock_CmnMfgSrv_CcaHwPartNr_GetErrorStatus: start-on-event=GetErrorStatus, operation=PSProxy_Rte_NvmBlock_CmnMfgSrv_CcaHwPartNr.GetErrorStatus
        OIT_GetErrorStatus_PSProxy_Rte_NvmBlock_CmnMfgSrv_CcaSerlNr_GetErrorStatus: start-on-event=GetErrorStatus, operation=PSProxy_Rte_NvmBlock_CmnMfgSrv_CcaSerlNr.GetErrorStatus
        OIT_GetErrorStatus_PSProxy_Rte_NvmBlock_CmnMfgSrv_DiRestore_GetErrorStatus: start-on-event=GetErrorStatus, operation=PSProxy_Rte_NvmBlock_CmnMfgSrv_DiRestore.GetErrorStatus
        OIT_GetErrorStatus_PSProxy_Rte_NvmBlock_CmnMfgSrv_EpsSysSerlNr_GetErrorStatus: start-on-event=GetErrorStatus, operation=PSProxy_Rte_NvmBlock_CmnMfgSrv_EpsSysSerlNr.GetErrorStatus
        OIT_GetErrorStatus_PSProxy_Rte_NvmBlock_CmnMfgSrv_IgnCntr_GetErrorStatus: start-on-event=GetErrorStatus, operation=PSProxy_Rte_NvmBlock_CmnMfgSrv_IgnCntr.GetErrorStatus
        OIT_GetErrorStatus_PSProxy_Rte_NvmBlock_CmnMfgSrv_MfgTmpBuf{0..4}_GetErrorStatus: start-on-event=GetErrorStatus, operation=PSProxy_Rte_NvmBlock_CmnMfgSrv_MfgTmpBuf{0..4}.GetErrorStatus
        OIT_GetErrorStatus_PSProxy_Rte_NvmBlock_CmnMfgSrv_NxtrMfgEnaCntr_GetErrorStatus: start-on-event=GetErrorStatus, operation=PSProxy_Rte_NvmBlock_CmnMfgSrv_NxtrMfgEnaCntr.GetErrorStatus
        OIT_GetErrorStatus_PSProxy_Rte_NvmBlock_DiagcMgr_DiagcMgrNtcFltAry_GetErrorStatus: start-on-event=GetErrorStatus, operation=PSProxy_Rte_NvmBlock_DiagcMgr_DiagcMgrNtcFltAry.GetErrorStatus
        OIT_GetErrorStatus_PSProxy_Rte_NvmBlock_DutyCycThermProtn_FilStVal_GetErrorStatus: start-on-event=GetErrorStatus, operation=PSProxy_Rte_NvmBlock_DutyCycThermProtn_FilStVal.GetErrorStatus
        OIT_GetErrorStatus_PSProxy_Rte_NvmBlock_EotLrng_EotNvmData_GetErrorStatus: start-on-event=GetErrorStatus, operation=PSProxy_Rte_NvmBlock_EotLrng_EotNvmData.GetErrorStatus
        OIT_GetErrorStatus_PSProxy_Rte_NvmBlock_HwAg0Meas_HwAg0Offs_GetErrorStatus: start-on-event=GetErrorStatus, operation=PSProxy_Rte_NvmBlock_HwAg0Meas_HwAg0Offs.GetErrorStatus
        OIT_GetErrorStatus_PSProxy_Rte_NvmBlock_HwAg1Meas_HwAg1Offs_GetErrorStatus: start-on-event=GetErrorStatus, operation=PSProxy_Rte_NvmBlock_HwAg1Meas_HwAg1Offs.GetErrorStatus
        OIT_GetErrorStatus_PSProxy_Rte_NvmBlock_HwTqCorrln_HwTqChACmnModCmpLpFilSt_GetErrorStatus: start-on-event=GetErrorStatus, operation=PSProxy_Rte_NvmBlock_HwTqCorrln_HwTqChACmnModCmpLpFilSt.GetErrorStatus
        OIT_GetErrorStatus_PSProxy_Rte_NvmBlock_HwTqCorrln_HwTqChBCmnModCmpLpFilSt_GetErrorStatus: start-on-event=GetErrorStatus, operation=PSProxy_Rte_NvmBlock_HwTqCorrln_HwTqChBCmnModCmpLpFilSt.GetErrorStatus
        OIT_GetErrorStatus_PSProxy_Rte_NvmBlock_MotAg2Meas_MtrAg2EolPrm_GetErrorStatus: start-on-event=GetErrorStatus, operation=PSProxy_Rte_NvmBlock_MotAg2Meas_MtrAg2EolPrm.GetErrorStatus
        OIT_GetErrorStatus_PSProxy_Rte_NvmBlock_NvMProxy_NvMProxyClsChkBlk_GetErrorStatus: start-on-event=GetErrorStatus, operation=PSProxy_Rte_NvmBlock_NvMProxy_NvMProxyClsChkBlk.GetErrorStatus
        OIT_GetErrorStatus_PSProxy_Rte_NvmBlock_PartNr_PartNrBasMdlPartNr_GetErrorStatus: start-on-event=GetErrorStatus, operation=PSProxy_Rte_NvmBlock_PartNr_PartNrBasMdlPartNr.GetErrorStatus
        OIT_GetErrorStatus_PSProxy_Rte_NvmBlock_PartNr_PartNrCalProgdSts_GetErrorStatus: start-on-event=GetErrorStatus, operation=PSProxy_Rte_NvmBlock_PartNr_PartNrCalProgdSts.GetErrorStatus
        OIT_GetErrorStatus_PSProxy_Rte_NvmBlock_PartNr_PartNrCcaMfgTrakg_GetErrorStatus: start-on-event=GetErrorStatus, operation=PSProxy_Rte_NvmBlock_PartNr_PartNrCcaMfgTrakg.GetErrorStatus
        OIT_GetErrorStatus_PSProxy_Rte_NvmBlock_PartNr_PartNrCtrlPidSeedKey_GetErrorStatus: start-on-event=GetErrorStatus, operation=PSProxy_Rte_NvmBlock_PartNr_PartNrCtrlPidSeedKey.GetErrorStatus
        OIT_GetErrorStatus_PSProxy_Rte_NvmBlock_PartNr_PartNrCustMfgEnaCntr_GetErrorStatus: start-on-event=GetErrorStatus, operation=PSProxy_Rte_NvmBlock_PartNr_PartNrCustMfgEnaCntr.GetErrorStatus
        OIT_GetErrorStatus_PSProxy_Rte_NvmBlock_PartNr_PartNrDataUniversalNrSysId_GetErrorStatus: start-on-event=GetErrorStatus, operation=PSProxy_Rte_NvmBlock_PartNr_PartNrDataUniversalNrSysId.GetErrorStatus
        OIT_GetErrorStatus_PSProxy_Rte_NvmBlock_PartNr_PartNrEndMdlPartNr_GetErrorStatus: start-on-event=GetErrorStatus, operation=PSProxy_Rte_NvmBlock_PartNr_PartNrEndMdlPartNr.GetErrorStatus
        OIT_GetErrorStatus_PSProxy_Rte_NvmBlock_PartNr_PartNrNxtrMfgTrakg_GetErrorStatus: start-on-event=GetErrorStatus, operation=PSProxy_Rte_NvmBlock_PartNr_PartNrNxtrMfgTrakg.GetErrorStatus
        OIT_GetErrorStatus_PSProxy_Rte_NvmBlock_PartNr_PartNrProgmDate_GetErrorStatus: start-on-event=GetErrorStatus, operation=PSProxy_Rte_NvmBlock_PartNr_PartNrProgmDate.GetErrorStatus
        OIT_GetErrorStatus_PSProxy_Rte_NvmBlock_PartNr_PartNrProgmSessionSeedKey_GetErrorStatus: start-on-event=GetErrorStatus, operation=PSProxy_Rte_NvmBlock_PartNr_PartNrProgmSessionSeedKey.GetErrorStatus
        OIT_GetErrorStatus_PSProxy_Rte_NvmBlock_PartNr_PartNrRepairShopCod_GetErrorStatus: start-on-event=GetErrorStatus, operation=PSProxy_Rte_NvmBlock_PartNr_PartNrRepairShopCod.GetErrorStatus
        OIT_GetErrorStatus_PSProxy_Rte_NvmBlock_PartNr_PartNrSysCodVersNr_GetErrorStatus: start-on-event=GetErrorStatus, operation=PSProxy_Rte_NvmBlock_PartNr_PartNrSysCodVersNr.GetErrorStatus
        OIT_GetErrorStatus_PSProxy_Rte_NvmBlock_PartNr_PartNrSysName_GetErrorStatus: start-on-event=GetErrorStatus, operation=PSProxy_Rte_NvmBlock_PartNr_PartNrSysName.GetErrorStatus
        OIT_GetErrorStatus_PSProxy_Rte_NvmBlock_PartNr_PartNrVinData_GetErrorStatus: start-on-event=GetErrorStatus, operation=PSProxy_Rte_NvmBlock_PartNr_PartNrVinData.GetErrorStatus
        OIT_GetErrorStatus_PSProxy_Rte_NvmBlock_PullCmpActv_PullCmpLongTerm_GetErrorStatus: start-on-event=GetErrorStatus, operation=PSProxy_Rte_NvmBlock_PullCmpActv_PullCmpLongTerm.GetErrorStatus
        OIT_InvalidateNvBlock_PSProxy_CurrMeasMotEol_Deprecated_InvalidateNvBlock: start-on-event=InvalidateNvBlock, operation=PSProxy_CurrMeasMotEol_Deprecated.InvalidateNvBlock
        OIT_InvalidateNvBlock_PSProxy_MotPrmNom_InvalidateNvBlock: start-on-event=InvalidateNvBlock, operation=PSProxy_MotPrmNom.InvalidateNvBlock
        OIT_InvalidateNvBlock_PSProxy_PolarityCfgSaved_InvalidateNvBlock: start-on-event=InvalidateNvBlock, operation=PSProxy_PolarityCfgSaved.InvalidateNvBlock
        OIT_InvalidateNvBlock_PSProxy_Rte_NvmBlock_CDD_CurrMeas_CurrMeasEolGainCalSet_InvalidateNvBlock: start-on-event=InvalidateNvBlock, operation=PSProxy_Rte_NvmBlock_CDD_CurrMeas_CurrMeasEolGainCalSet.InvalidateNvBlock
        OIT_InvalidateNvBlock_PSProxy_Rte_NvmBlock_CDD_CurrMeas_CurrMeasEolOffsCalSet_InvalidateNvBlock: start-on-event=InvalidateNvBlock, operation=PSProxy_Rte_NvmBlock_CDD_CurrMeas_CurrMeasEolOffsCalSet.InvalidateNvBlock
        OIT_InvalidateNvBlock_PSProxy_Rte_NvmBlock_CDD_HwTq{0..3}Meas_HwTq{0..3}Offs_InvalidateNvBlock: start-on-event=InvalidateNvBlock, operation=PSProxy_Rte_NvmBlock_CDD_HwTq{0..3}Meas_HwTq{0..3}Offs.InvalidateNvBlock
        OIT_InvalidateNvBlock_PSProxy_Rte_NvmBlock_CDD_MotAg0Meas_MotAg0CoeffTbl_InvalidateNvBlock: start-on-event=InvalidateNvBlock, operation=PSProxy_Rte_NvmBlock_CDD_MotAg0Meas_MotAg0CoeffTbl.InvalidateNvBlock
        OIT_InvalidateNvBlock_PSProxy_Rte_NvmBlock_CDD_MotAg1Meas_MotAg1CoeffTbl_InvalidateNvBlock: start-on-event=InvalidateNvBlock, operation=PSProxy_Rte_NvmBlock_CDD_MotAg1Meas_MotAg1CoeffTbl.InvalidateNvBlock
        OIT_InvalidateNvBlock_PSProxy_Rte_NvmBlock_CDD_MotAgCmp_MotAgCmpMotAgBackEmf_InvalidateNvBlock: start-on-event=InvalidateNvBlock, operation=PSProxy_Rte_NvmBlock_CDD_MotAgCmp_MotAgCmpMotAgBackEmf.InvalidateNvBlock
        OIT_InvalidateNvBlock_PSProxy_Rte_NvmBlock_CmnMfgSrv_CcaHwPartNr_InvalidateNvBlock: start-on-event=InvalidateNvBlock, operation=PSProxy_Rte_NvmBlock_CmnMfgSrv_CcaHwPartNr.InvalidateNvBlock
        OIT_InvalidateNvBlock_PSProxy_Rte_NvmBlock_CmnMfgSrv_CcaSerlNr_InvalidateNvBlock: start-on-event=InvalidateNvBlock, operation=PSProxy_Rte_NvmBlock_CmnMfgSrv_CcaSerlNr.InvalidateNvBlock
        OIT_InvalidateNvBlock_PSProxy_Rte_NvmBlock_CmnMfgSrv_DiRestore_InvalidateNvBlock: start-on-event=InvalidateNvBlock, operation=PSProxy_Rte_NvmBlock_CmnMfgSrv_DiRestore.InvalidateNvBlock
        OIT_InvalidateNvBlock_PSProxy_Rte_NvmBlock_CmnMfgSrv_EpsSysSerlNr_InvalidateNvBlock: start-on-event=InvalidateNvBlock, operation=PSProxy_Rte_NvmBlock_CmnMfgSrv_EpsSysSerlNr.InvalidateNvBlock
        OIT_InvalidateNvBlock_PSProxy_Rte_NvmBlock_CmnMfgSrv_IgnCntr_InvalidateNvBlock: start-on-event=InvalidateNvBlock, operation=PSProxy_Rte_NvmBlock_CmnMfgSrv_IgnCntr.InvalidateNvBlock
        OIT_InvalidateNvBlock_PSProxy_Rte_NvmBlock_CmnMfgSrv_MfgTmpBuf{0..4}_InvalidateNvBlock: start-on-event=InvalidateNvBlock, operation=PSProxy_Rte_NvmBlock_CmnMfgSrv_MfgTmpBuf{0..4}.InvalidateNvBlock
        OIT_InvalidateNvBlock_PSProxy_Rte_NvmBlock_CmnMfgSrv_NxtrMfgEnaCntr_InvalidateNvBlock: start-on-event=InvalidateNvBlock, operation=PSProxy_Rte_NvmBlock_CmnMfgSrv_NxtrMfgEnaCntr.InvalidateNvBlock
        OIT_InvalidateNvBlock_PSProxy_Rte_NvmBlock_DiagcMgr_DiagcMgrNtcFltAry_InvalidateNvBlock: start-on-event=InvalidateNvBlock, operation=PSProxy_Rte_NvmBlock_DiagcMgr_DiagcMgrNtcFltAry.InvalidateNvBlock
        OIT_InvalidateNvBlock_PSProxy_Rte_NvmBlock_DutyCycThermProtn_FilStVal_InvalidateNvBlock: start-on-event=InvalidateNvBlock, operation=PSProxy_Rte_NvmBlock_DutyCycThermProtn_FilStVal.InvalidateNvBlock
        OIT_InvalidateNvBlock_PSProxy_Rte_NvmBlock_EotLrng_EotNvmData_InvalidateNvBlock: start-on-event=InvalidateNvBlock, operation=PSProxy_Rte_NvmBlock_EotLrng_EotNvmData.InvalidateNvBlock
        OIT_InvalidateNvBlock_PSProxy_Rte_NvmBlock_HwAg0Meas_HwAg0Offs_InvalidateNvBlock: start-on-event=InvalidateNvBlock, operation=PSProxy_Rte_NvmBlock_HwAg0Meas_HwAg0Offs.InvalidateNvBlock
        OIT_InvalidateNvBlock_PSProxy_Rte_NvmBlock_HwAg1Meas_HwAg1Offs_InvalidateNvBlock: start-on-event=InvalidateNvBlock, operation=PSProxy_Rte_NvmBlock_HwAg1Meas_HwAg1Offs.InvalidateNvBlock
        OIT_InvalidateNvBlock_PSProxy_Rte_NvmBlock_HwTqCorrln_HwTqChACmnModCmpLpFilSt_InvalidateNvBlock: start-on-event=InvalidateNvBlock, operation=PSProxy_Rte_NvmBlock_HwTqCorrln_HwTqChACmnModCmpLpFilSt.InvalidateNvBlock
        OIT_InvalidateNvBlock_PSProxy_Rte_NvmBlock_HwTqCorrln_HwTqChBCmnModCmpLpFilSt_InvalidateNvBlock: start-on-event=InvalidateNvBlock, operation=PSProxy_Rte_NvmBlock_HwTqCorrln_HwTqChBCmnModCmpLpFilSt.InvalidateNvBlock
        OIT_InvalidateNvBlock_PSProxy_Rte_NvmBlock_MotAg2Meas_MtrAg2EolPrm_InvalidateNvBlock: start-on-event=InvalidateNvBlock, operation=PSProxy_Rte_NvmBlock_MotAg2Meas_MtrAg2EolPrm.InvalidateNvBlock
        OIT_InvalidateNvBlock_PSProxy_Rte_NvmBlock_NvMProxy_NvMProxyClsChkBlk_InvalidateNvBlock: start-on-event=InvalidateNvBlock, operation=PSProxy_Rte_NvmBlock_NvMProxy_NvMProxyClsChkBlk.InvalidateNvBlock
        OIT_InvalidateNvBlock_PSProxy_Rte_NvmBlock_PartNr_PartNrBasMdlPartNr_InvalidateNvBlock: start-on-event=InvalidateNvBlock, operation=PSProxy_Rte_NvmBlock_PartNr_PartNrBasMdlPartNr.InvalidateNvBlock
        OIT_InvalidateNvBlock_PSProxy_Rte_NvmBlock_PartNr_PartNrCalProgdSts_InvalidateNvBlock: start-on-event=InvalidateNvBlock, operation=PSProxy_Rte_NvmBlock_PartNr_PartNrCalProgdSts.InvalidateNvBlock
        OIT_InvalidateNvBlock_PSProxy_Rte_NvmBlock_PartNr_PartNrCcaMfgTrakg_InvalidateNvBlock: start-on-event=InvalidateNvBlock, operation=PSProxy_Rte_NvmBlock_PartNr_PartNrCcaMfgTrakg.InvalidateNvBlock
        OIT_InvalidateNvBlock_PSProxy_Rte_NvmBlock_PartNr_PartNrCtrlPidSeedKey_InvalidateNvBlock: start-on-event=InvalidateNvBlock, operation=PSProxy_Rte_NvmBlock_PartNr_PartNrCtrlPidSeedKey.InvalidateNvBlock
        OIT_InvalidateNvBlock_PSProxy_Rte_NvmBlock_PartNr_PartNrCustMfgEnaCntr_InvalidateNvBlock: start-on-event=InvalidateNvBlock, operation=PSProxy_Rte_NvmBlock_PartNr_PartNrCustMfgEnaCntr.InvalidateNvBlock
        OIT_InvalidateNvBlock_PSProxy_Rte_NvmBlock_PartNr_PartNrDataUniversalNrSysId_InvalidateNvBlock: start-on-event=InvalidateNvBlock, operation=PSProxy_Rte_NvmBlock_PartNr_PartNrDataUniversalNrSysId.InvalidateNvBlock
        OIT_InvalidateNvBlock_PSProxy_Rte_NvmBlock_PartNr_PartNrEndMdlPartNr_InvalidateNvBlock: start-on-event=InvalidateNvBlock, operation=PSProxy_Rte_NvmBlock_PartNr_PartNrEndMdlPartNr.InvalidateNvBlock
        OIT_InvalidateNvBlock_PSProxy_Rte_NvmBlock_PartNr_PartNrNxtrMfgTrakg_InvalidateNvBlock: start-on-event=InvalidateNvBlock, operation=PSProxy_Rte_NvmBlock_PartNr_PartNrNxtrMfgTrakg.InvalidateNvBlock
        OIT_InvalidateNvBlock_PSProxy_Rte_NvmBlock_PartNr_PartNrProgmDate_InvalidateNvBlock: start-on-event=InvalidateNvBlock, operation=PSProxy_Rte_NvmBlock_PartNr_PartNrProgmDate.InvalidateNvBlock
        OIT_InvalidateNvBlock_PSProxy_Rte_NvmBlock_PartNr_PartNrProgmSessionSeedKey_InvalidateNvBlock: start-on-event=InvalidateNvBlock, operation=PSProxy_Rte_NvmBlock_PartNr_PartNrProgmSessionSeedKey.InvalidateNvBlock
        OIT_InvalidateNvBlock_PSProxy_Rte_NvmBlock_PartNr_PartNrRepairShopCod_InvalidateNvBlock: start-on-event=InvalidateNvBlock, operation=PSProxy_Rte_NvmBlock_PartNr_PartNrRepairShopCod.InvalidateNvBlock
        OIT_InvalidateNvBlock_PSProxy_Rte_NvmBlock_PartNr_PartNrSysCodVersNr_InvalidateNvBlock: start-on-event=InvalidateNvBlock, operation=PSProxy_Rte_NvmBlock_PartNr_PartNrSysCodVersNr.InvalidateNvBlock
        OIT_InvalidateNvBlock_PSProxy_Rte_NvmBlock_PartNr_PartNrSysName_InvalidateNvBlock: start-on-event=InvalidateNvBlock, operation=PSProxy_Rte_NvmBlock_PartNr_PartNrSysName.InvalidateNvBlock
        OIT_InvalidateNvBlock_PSProxy_Rte_NvmBlock_PartNr_PartNrVinData_InvalidateNvBlock: start-on-event=InvalidateNvBlock, operation=PSProxy_Rte_NvmBlock_PartNr_PartNrVinData.InvalidateNvBlock
        OIT_InvalidateNvBlock_PSProxy_Rte_NvmBlock_PullCmpActv_PullCmpLongTerm_InvalidateNvBlock: start-on-event=InvalidateNvBlock, operation=PSProxy_Rte_NvmBlock_PullCmpActv_PullCmpLongTerm.InvalidateNvBlock
      timing event Timer_CDD_NvMProxy_MainFunction: start-on-event=CDD_NvMProxy_MainFunction, period=0.01
      221 x operation invoked event:
        OIT_ReadBlock_PSProxy_CurrMeasMotEol_Deprecated_ReadBlock: start-on-event=ReadBlock, operation=PSProxy_CurrMeasMotEol_Deprecated.ReadBlock
        OIT_ReadBlock_PSProxy_MotPrmNom_ReadBlock: start-on-event=ReadBlock, operation=PSProxy_MotPrmNom.ReadBlock
        OIT_ReadBlock_PSProxy_PolarityCfgSaved_ReadBlock: start-on-event=ReadBlock, operation=PSProxy_PolarityCfgSaved.ReadBlock
        OIT_ReadBlock_PSProxy_Rte_NvmBlock_CDD_CurrMeas_CurrMeasEolGainCalSet_ReadBlock: start-on-event=ReadBlock, operation=PSProxy_Rte_NvmBlock_CDD_CurrMeas_CurrMeasEolGainCalSet.ReadBlock
        OIT_ReadBlock_PSProxy_Rte_NvmBlock_CDD_CurrMeas_CurrMeasEolOffsCalSet_ReadBlock: start-on-event=ReadBlock, operation=PSProxy_Rte_NvmBlock_CDD_CurrMeas_CurrMeasEolOffsCalSet.ReadBlock
        OIT_ReadBlock_PSProxy_Rte_NvmBlock_CDD_HwTq{0..3}Meas_HwTq{0..3}Offs_ReadBlock: start-on-event=ReadBlock, operation=PSProxy_Rte_NvmBlock_CDD_HwTq{0..3}Meas_HwTq{0..3}Offs.ReadBlock
        OIT_ReadBlock_PSProxy_Rte_NvmBlock_CDD_MotAg0Meas_MotAg0CoeffTbl_ReadBlock: start-on-event=ReadBlock, operation=PSProxy_Rte_NvmBlock_CDD_MotAg0Meas_MotAg0CoeffTbl.ReadBlock
        OIT_ReadBlock_PSProxy_Rte_NvmBlock_CDD_MotAg1Meas_MotAg1CoeffTbl_ReadBlock: start-on-event=ReadBlock, operation=PSProxy_Rte_NvmBlock_CDD_MotAg1Meas_MotAg1CoeffTbl.ReadBlock
        OIT_ReadBlock_PSProxy_Rte_NvmBlock_CDD_MotAgCmp_MotAgCmpMotAgBackEmf_ReadBlock: start-on-event=ReadBlock, operation=PSProxy_Rte_NvmBlock_CDD_MotAgCmp_MotAgCmpMotAgBackEmf.ReadBlock
        OIT_ReadBlock_PSProxy_Rte_NvmBlock_CmnMfgSrv_CcaHwPartNr_ReadBlock: start-on-event=ReadBlock, operation=PSProxy_Rte_NvmBlock_CmnMfgSrv_CcaHwPartNr.ReadBlock
        OIT_ReadBlock_PSProxy_Rte_NvmBlock_CmnMfgSrv_CcaSerlNr_ReadBlock: start-on-event=ReadBlock, operation=PSProxy_Rte_NvmBlock_CmnMfgSrv_CcaSerlNr.ReadBlock
        OIT_ReadBlock_PSProxy_Rte_NvmBlock_CmnMfgSrv_DiRestore_ReadBlock: start-on-event=ReadBlock, operation=PSProxy_Rte_NvmBlock_CmnMfgSrv_DiRestore.ReadBlock
        OIT_ReadBlock_PSProxy_Rte_NvmBlock_CmnMfgSrv_EpsSysSerlNr_ReadBlock: start-on-event=ReadBlock, operation=PSProxy_Rte_NvmBlock_CmnMfgSrv_EpsSysSerlNr.ReadBlock
        OIT_ReadBlock_PSProxy_Rte_NvmBlock_CmnMfgSrv_IgnCntr_ReadBlock: start-on-event=ReadBlock, operation=PSProxy_Rte_NvmBlock_CmnMfgSrv_IgnCntr.ReadBlock
        OIT_ReadBlock_PSProxy_Rte_NvmBlock_CmnMfgSrv_MfgTmpBuf{0..4}_ReadBlock: start-on-event=ReadBlock, operation=PSProxy_Rte_NvmBlock_CmnMfgSrv_MfgTmpBuf{0..4}.ReadBlock
        OIT_ReadBlock_PSProxy_Rte_NvmBlock_CmnMfgSrv_NxtrMfgEnaCntr_ReadBlock: start-on-event=ReadBlock, operation=PSProxy_Rte_NvmBlock_CmnMfgSrv_NxtrMfgEnaCntr.ReadBlock
        OIT_ReadBlock_PSProxy_Rte_NvmBlock_DiagcMgr_DiagcMgrNtcFltAry_ReadBlock: start-on-event=ReadBlock, operation=PSProxy_Rte_NvmBlock_DiagcMgr_DiagcMgrNtcFltAry.ReadBlock
        OIT_ReadBlock_PSProxy_Rte_NvmBlock_DutyCycThermProtn_FilStVal_ReadBlock: start-on-event=ReadBlock, operation=PSProxy_Rte_NvmBlock_DutyCycThermProtn_FilStVal.ReadBlock
        OIT_ReadBlock_PSProxy_Rte_NvmBlock_EotLrng_EotNvmData_ReadBlock: start-on-event=ReadBlock, operation=PSProxy_Rte_NvmBlock_EotLrng_EotNvmData.ReadBlock
        OIT_ReadBlock_PSProxy_Rte_NvmBlock_HwAg0Meas_HwAg0Offs_ReadBlock: start-on-event=ReadBlock, operation=PSProxy_Rte_NvmBlock_HwAg0Meas_HwAg0Offs.ReadBlock
        OIT_ReadBlock_PSProxy_Rte_NvmBlock_HwAg1Meas_HwAg1Offs_ReadBlock: start-on-event=ReadBlock, operation=PSProxy_Rte_NvmBlock_HwAg1Meas_HwAg1Offs.ReadBlock
        OIT_ReadBlock_PSProxy_Rte_NvmBlock_HwTqCorrln_HwTqChACmnModCmpLpFilSt_ReadBlock: start-on-event=ReadBlock, operation=PSProxy_Rte_NvmBlock_HwTqCorrln_HwTqChACmnModCmpLpFilSt.ReadBlock
        OIT_ReadBlock_PSProxy_Rte_NvmBlock_HwTqCorrln_HwTqChBCmnModCmpLpFilSt_ReadBlock: start-on-event=ReadBlock, operation=PSProxy_Rte_NvmBlock_HwTqCorrln_HwTqChBCmnModCmpLpFilSt.ReadBlock
        OIT_ReadBlock_PSProxy_Rte_NvmBlock_MotAg2Meas_MtrAg2EolPrm_ReadBlock: start-on-event=ReadBlock, operation=PSProxy_Rte_NvmBlock_MotAg2Meas_MtrAg2EolPrm.ReadBlock
        OIT_ReadBlock_PSProxy_Rte_NvmBlock_NvMProxy_NvMProxyClsChkBlk_ReadBlock: start-on-event=ReadBlock, operation=PSProxy_Rte_NvmBlock_NvMProxy_NvMProxyClsChkBlk.ReadBlock
        OIT_ReadBlock_PSProxy_Rte_NvmBlock_PartNr_PartNrBasMdlPartNr_ReadBlock: start-on-event=ReadBlock, operation=PSProxy_Rte_NvmBlock_PartNr_PartNrBasMdlPartNr.ReadBlock
        OIT_ReadBlock_PSProxy_Rte_NvmBlock_PartNr_PartNrCalProgdSts_ReadBlock: start-on-event=ReadBlock, operation=PSProxy_Rte_NvmBlock_PartNr_PartNrCalProgdSts.ReadBlock
        OIT_ReadBlock_PSProxy_Rte_NvmBlock_PartNr_PartNrCcaMfgTrakg_ReadBlock: start-on-event=ReadBlock, operation=PSProxy_Rte_NvmBlock_PartNr_PartNrCcaMfgTrakg.ReadBlock
        OIT_ReadBlock_PSProxy_Rte_NvmBlock_PartNr_PartNrCtrlPidSeedKey_ReadBlock: start-on-event=ReadBlock, operation=PSProxy_Rte_NvmBlock_PartNr_PartNrCtrlPidSeedKey.ReadBlock
        OIT_ReadBlock_PSProxy_Rte_NvmBlock_PartNr_PartNrCustMfgEnaCntr_ReadBlock: start-on-event=ReadBlock, operation=PSProxy_Rte_NvmBlock_PartNr_PartNrCustMfgEnaCntr.ReadBlock
        OIT_ReadBlock_PSProxy_Rte_NvmBlock_PartNr_PartNrDataUniversalNrSysId_ReadBlock: start-on-event=ReadBlock, operation=PSProxy_Rte_NvmBlock_PartNr_PartNrDataUniversalNrSysId.ReadBlock
        OIT_ReadBlock_PSProxy_Rte_NvmBlock_PartNr_PartNrEndMdlPartNr_ReadBlock: start-on-event=ReadBlock, operation=PSProxy_Rte_NvmBlock_PartNr_PartNrEndMdlPartNr.ReadBlock
        OIT_ReadBlock_PSProxy_Rte_NvmBlock_PartNr_PartNrNxtrMfgTrakg_ReadBlock: start-on-event=ReadBlock, operation=PSProxy_Rte_NvmBlock_PartNr_PartNrNxtrMfgTrakg.ReadBlock
        OIT_ReadBlock_PSProxy_Rte_NvmBlock_PartNr_PartNrProgmDate_ReadBlock: start-on-event=ReadBlock, operation=PSProxy_Rte_NvmBlock_PartNr_PartNrProgmDate.ReadBlock
        OIT_ReadBlock_PSProxy_Rte_NvmBlock_PartNr_PartNrProgmSessionSeedKey_ReadBlock: start-on-event=ReadBlock, operation=PSProxy_Rte_NvmBlock_PartNr_PartNrProgmSessionSeedKey.ReadBlock
        OIT_ReadBlock_PSProxy_Rte_NvmBlock_PartNr_PartNrRepairShopCod_ReadBlock: start-on-event=ReadBlock, operation=PSProxy_Rte_NvmBlock_PartNr_PartNrRepairShopCod.ReadBlock
        OIT_ReadBlock_PSProxy_Rte_NvmBlock_PartNr_PartNrSysCodVersNr_ReadBlock: start-on-event=ReadBlock, operation=PSProxy_Rte_NvmBlock_PartNr_PartNrSysCodVersNr.ReadBlock
        OIT_ReadBlock_PSProxy_Rte_NvmBlock_PartNr_PartNrSysName_ReadBlock: start-on-event=ReadBlock, operation=PSProxy_Rte_NvmBlock_PartNr_PartNrSysName.ReadBlock
        OIT_ReadBlock_PSProxy_Rte_NvmBlock_PartNr_PartNrVinData_ReadBlock: start-on-event=ReadBlock, operation=PSProxy_Rte_NvmBlock_PartNr_PartNrVinData.ReadBlock
        OIT_ReadBlock_PSProxy_Rte_NvmBlock_PullCmpActv_PullCmpLongTerm_ReadBlock: start-on-event=ReadBlock, operation=PSProxy_Rte_NvmBlock_PullCmpActv_PullCmpLongTerm.ReadBlock
        OIT_RestoreBlockDefaults_PSProxy_Rte_NvmBlock_CDD_CurrMeas_CurrMeasEolGainCalSet_RestoreBlockDefaults: start-on-event=RestoreBlockDefaults, operation=PSProxy_Rte_NvmBlock_CDD_CurrMeas_CurrMeasEolGainCalSet.RestoreBlockDefaults
        OIT_RestoreBlockDefaults_PSProxy_Rte_NvmBlock_CDD_CurrMeas_CurrMeasEolOffsCalSet_RestoreBlockDefaults: start-on-event=RestoreBlockDefaults, operation=PSProxy_Rte_NvmBlock_CDD_CurrMeas_CurrMeasEolOffsCalSet.RestoreBlockDefaults
        OIT_RestoreBlockDefaults_PSProxy_Rte_NvmBlock_CDD_HwTq{0..3}Meas_HwTq{0..3}Offs_RestoreBlockDefaults: start-on-event=RestoreBlockDefaults, operation=PSProxy_Rte_NvmBlock_CDD_HwTq{0..3}Meas_HwTq{0..3}Offs.RestoreBlockDefaults
        OIT_RestoreBlockDefaults_PSProxy_Rte_NvmBlock_CDD_MotAg0Meas_MotAg0CoeffTbl_RestoreBlockDefaults: start-on-event=RestoreBlockDefaults, operation=PSProxy_Rte_NvmBlock_CDD_MotAg0Meas_MotAg0CoeffTbl.RestoreBlockDefaults
        OIT_RestoreBlockDefaults_PSProxy_Rte_NvmBlock_CDD_MotAg1Meas_MotAg1CoeffTbl_RestoreBlockDefaults: start-on-event=RestoreBlockDefaults, operation=PSProxy_Rte_NvmBlock_CDD_MotAg1Meas_MotAg1CoeffTbl.RestoreBlockDefaults
        OIT_RestoreBlockDefaults_PSProxy_Rte_NvmBlock_CDD_MotAgCmp_MotAgCmpMotAgBackEmf_RestoreBlockDefaults: start-on-event=RestoreBlockDefaults, operation=PSProxy_Rte_NvmBlock_CDD_MotAgCmp_MotAgCmpMotAgBackEmf.RestoreBlockDefaults
        OIT_RestoreBlockDefaults_PSProxy_Rte_NvmBlock_CmnMfgSrv_IgnCntr_RestoreBlockDefaults: start-on-event=RestoreBlockDefaults, operation=PSProxy_Rte_NvmBlock_CmnMfgSrv_IgnCntr.RestoreBlockDefaults
        OIT_RestoreBlockDefaults_PSProxy_Rte_NvmBlock_CmnMfgSrv_NxtrMfgEnaCntr_RestoreBlockDefaults: start-on-event=RestoreBlockDefaults, operation=PSProxy_Rte_NvmBlock_CmnMfgSrv_NxtrMfgEnaCntr.RestoreBlockDefaults
        OIT_RestoreBlockDefaults_PSProxy_Rte_NvmBlock_DutyCycThermProtn_FilStVal_RestoreBlockDefaults: start-on-event=RestoreBlockDefaults, operation=PSProxy_Rte_NvmBlock_DutyCycThermProtn_FilStVal.RestoreBlockDefaults
        OIT_RestoreBlockDefaults_PSProxy_Rte_NvmBlock_EotLrng_EotNvmData_RestoreBlockDefaults: start-on-event=RestoreBlockDefaults, operation=PSProxy_Rte_NvmBlock_EotLrng_EotNvmData.RestoreBlockDefaults
        OIT_RestoreBlockDefaults_PSProxy_Rte_NvmBlock_HwAg0Meas_HwAg0Offs_RestoreBlockDefaults: start-on-event=RestoreBlockDefaults, operation=PSProxy_Rte_NvmBlock_HwAg0Meas_HwAg0Offs.RestoreBlockDefaults
        OIT_RestoreBlockDefaults_PSProxy_Rte_NvmBlock_HwAg1Meas_HwAg1Offs_RestoreBlockDefaults: start-on-event=RestoreBlockDefaults, operation=PSProxy_Rte_NvmBlock_HwAg1Meas_HwAg1Offs.RestoreBlockDefaults
        OIT_RestoreBlockDefaults_PSProxy_Rte_NvmBlock_HwTqCorrln_HwTqChACmnModCmpLpFilSt_RestoreBlockDefaults: start-on-event=RestoreBlockDefaults, operation=PSProxy_Rte_NvmBlock_HwTqCorrln_HwTqChACmnModCmpLpFilSt.RestoreBlockDefaults
        OIT_RestoreBlockDefaults_PSProxy_Rte_NvmBlock_HwTqCorrln_HwTqChBCmnModCmpLpFilSt_RestoreBlockDefaults: start-on-event=RestoreBlockDefaults, operation=PSProxy_Rte_NvmBlock_HwTqCorrln_HwTqChBCmnModCmpLpFilSt.RestoreBlockDefaults
        OIT_RestoreBlockDefaults_PSProxy_Rte_NvmBlock_MotAg2Meas_MtrAg2EolPrm_RestoreBlockDefaults: start-on-event=RestoreBlockDefaults, operation=PSProxy_Rte_NvmBlock_MotAg2Meas_MtrAg2EolPrm.RestoreBlockDefaults
        OIT_RestoreBlockDefaults_PSProxy_Rte_NvmBlock_PartNr_PartNrBasMdlPartNr_RestoreBlockDefaults: start-on-event=RestoreBlockDefaults, operation=PSProxy_Rte_NvmBlock_PartNr_PartNrBasMdlPartNr.RestoreBlockDefaults
        OIT_RestoreBlockDefaults_PSProxy_Rte_NvmBlock_PartNr_PartNrCalProgdSts_RestoreBlockDefaults: start-on-event=RestoreBlockDefaults, operation=PSProxy_Rte_NvmBlock_PartNr_PartNrCalProgdSts.RestoreBlockDefaults
        OIT_RestoreBlockDefaults_PSProxy_Rte_NvmBlock_PartNr_PartNrCcaMfgTrakg_RestoreBlockDefaults: start-on-event=RestoreBlockDefaults, operation=PSProxy_Rte_NvmBlock_PartNr_PartNrCcaMfgTrakg.RestoreBlockDefaults
        OIT_RestoreBlockDefaults_PSProxy_Rte_NvmBlock_PartNr_PartNrCtrlPidSeedKey_RestoreBlockDefaults: start-on-event=RestoreBlockDefaults, operation=PSProxy_Rte_NvmBlock_PartNr_PartNrCtrlPidSeedKey.RestoreBlockDefaults
        OIT_RestoreBlockDefaults_PSProxy_Rte_NvmBlock_PartNr_PartNrCustMfgEnaCntr_RestoreBlockDefaults: start-on-event=RestoreBlockDefaults, operation=PSProxy_Rte_NvmBlock_PartNr_PartNrCustMfgEnaCntr.RestoreBlockDefaults
        OIT_RestoreBlockDefaults_PSProxy_Rte_NvmBlock_PartNr_PartNrDataUniversalNrSysId_RestoreBlockDefaults: start-on-event=RestoreBlockDefaults, operation=PSProxy_Rte_NvmBlock_PartNr_PartNrDataUniversalNrSysId.RestoreBlockDefaults
        OIT_RestoreBlockDefaults_PSProxy_Rte_NvmBlock_PartNr_PartNrEndMdlPartNr_RestoreBlockDefaults: start-on-event=RestoreBlockDefaults, operation=PSProxy_Rte_NvmBlock_PartNr_PartNrEndMdlPartNr.RestoreBlockDefaults
        OIT_RestoreBlockDefaults_PSProxy_Rte_NvmBlock_PartNr_PartNrNxtrMfgTrakg_RestoreBlockDefaults: start-on-event=RestoreBlockDefaults, operation=PSProxy_Rte_NvmBlock_PartNr_PartNrNxtrMfgTrakg.RestoreBlockDefaults
        OIT_RestoreBlockDefaults_PSProxy_Rte_NvmBlock_PartNr_PartNrProgmDate_RestoreBlockDefaults: start-on-event=RestoreBlockDefaults, operation=PSProxy_Rte_NvmBlock_PartNr_PartNrProgmDate.RestoreBlockDefaults
        OIT_RestoreBlockDefaults_PSProxy_Rte_NvmBlock_PartNr_PartNrProgmSessionSeedKey_RestoreBlockDefaults: start-on-event=RestoreBlockDefaults, operation=PSProxy_Rte_NvmBlock_PartNr_PartNrProgmSessionSeedKey.RestoreBlockDefaults
        OIT_RestoreBlockDefaults_PSProxy_Rte_NvmBlock_PartNr_PartNrRepairShopCod_RestoreBlockDefaults: start-on-event=RestoreBlockDefaults, operation=PSProxy_Rte_NvmBlock_PartNr_PartNrRepairShopCod.RestoreBlockDefaults
        OIT_RestoreBlockDefaults_PSProxy_Rte_NvmBlock_PartNr_PartNrSysCodVersNr_RestoreBlockDefaults: start-on-event=RestoreBlockDefaults, operation=PSProxy_Rte_NvmBlock_PartNr_PartNrSysCodVersNr.RestoreBlockDefaults
        OIT_RestoreBlockDefaults_PSProxy_Rte_NvmBlock_PartNr_PartNrSysName_RestoreBlockDefaults: start-on-event=RestoreBlockDefaults, operation=PSProxy_Rte_NvmBlock_PartNr_PartNrSysName.RestoreBlockDefaults
        OIT_RestoreBlockDefaults_PSProxy_Rte_NvmBlock_PartNr_PartNrVinData_RestoreBlockDefaults: start-on-event=RestoreBlockDefaults, operation=PSProxy_Rte_NvmBlock_PartNr_PartNrVinData.RestoreBlockDefaults
        OIT_RestoreBlockDefaults_PSProxy_Rte_NvmBlock_PullCmpActv_PullCmpLongTerm_RestoreBlockDefaults: start-on-event=RestoreBlockDefaults, operation=PSProxy_Rte_NvmBlock_PullCmpActv_PullCmpLongTerm.RestoreBlockDefaults
        OIT_SetBlockProtection_PAdminProxy_CurrMeasMotEol_Deprecated_SetBlockProtection: start-on-event=SetBlockProtection, operation=PAdminProxy_CurrMeasMotEol_Deprecated.SetBlockProtection
        OIT_SetBlockProtection_PAdminProxy_MotPrmNom_SetBlockProtection: start-on-event=SetBlockProtection, operation=PAdminProxy_MotPrmNom.SetBlockProtection
        OIT_SetBlockProtection_PAdminProxy_PolarityCfgSaved_SetBlockProtection: start-on-event=SetBlockProtection, operation=PAdminProxy_PolarityCfgSaved.SetBlockProtection
        OIT_SetBlockProtection_PAdminProxy_Rte_NvmBlock_CDD_CurrMeas_CurrMeasEolGainCalSet_SetBlockProtection: start-on-event=SetBlockProtection, operation=PAdminProxy_Rte_NvmBlock_CDD_CurrMeas_CurrMeasEolGainCalSet.SetBlockProtection
        OIT_SetBlockProtection_PAdminProxy_Rte_NvmBlock_CDD_CurrMeas_CurrMeasEolOffsCalSet_SetBlockProtection: start-on-event=SetBlockProtection, operation=PAdminProxy_Rte_NvmBlock_CDD_CurrMeas_CurrMeasEolOffsCalSet.SetBlockProtection
        OIT_SetBlockProtection_PAdminProxy_Rte_NvmBlock_CDD_HwTq{0..3}Meas_HwTq{0..3}Offs_SetBlockProtection: start-on-event=SetBlockProtection, operation=PAdminProxy_Rte_NvmBlock_CDD_HwTq{0..3}Meas_HwTq{0..3}Offs.SetBlockProtection
        OIT_SetBlockProtection_PAdminProxy_Rte_NvmBlock_CDD_MotAg0Meas_MotAg0CoeffTbl_SetBlockProtection: start-on-event=SetBlockProtection, operation=PAdminProxy_Rte_NvmBlock_CDD_MotAg0Meas_MotAg0CoeffTbl.SetBlockProtection
        OIT_SetBlockProtection_PAdminProxy_Rte_NvmBlock_CDD_MotAg1Meas_MotAg1CoeffTbl_SetBlockProtection: start-on-event=SetBlockProtection, operation=PAdminProxy_Rte_NvmBlock_CDD_MotAg1Meas_MotAg1CoeffTbl.SetBlockProtection
        OIT_SetBlockProtection_PAdminProxy_Rte_NvmBlock_CDD_MotAgCmp_MotAgCmpMotAgBackEmf_SetBlockProtection: start-on-event=SetBlockProtection, operation=PAdminProxy_Rte_NvmBlock_CDD_MotAgCmp_MotAgCmpMotAgBackEmf.SetBlockProtection
        OIT_SetBlockProtection_PAdminProxy_Rte_NvmBlock_CmnMfgSrv_CcaHwPartNr_SetBlockProtection: start-on-event=SetBlockProtection, operation=PAdminProxy_Rte_NvmBlock_CmnMfgSrv_CcaHwPartNr.SetBlockProtection
        OIT_SetBlockProtection_PAdminProxy_Rte_NvmBlock_CmnMfgSrv_CcaSerlNr_SetBlockProtection: start-on-event=SetBlockProtection, operation=PAdminProxy_Rte_NvmBlock_CmnMfgSrv_CcaSerlNr.SetBlockProtection
        OIT_SetBlockProtection_PAdminProxy_Rte_NvmBlock_CmnMfgSrv_DiRestore_SetBlockProtection: start-on-event=SetBlockProtection, operation=PAdminProxy_Rte_NvmBlock_CmnMfgSrv_DiRestore.SetBlockProtection
        OIT_SetBlockProtection_PAdminProxy_Rte_NvmBlock_CmnMfgSrv_EpsSysSerlNr_SetBlockProtection: start-on-event=SetBlockProtection, operation=PAdminProxy_Rte_NvmBlock_CmnMfgSrv_EpsSysSerlNr.SetBlockProtection
        OIT_SetBlockProtection_PAdminProxy_Rte_NvmBlock_CmnMfgSrv_IgnCntr_SetBlockProtection: start-on-event=SetBlockProtection, operation=PAdminProxy_Rte_NvmBlock_CmnMfgSrv_IgnCntr.SetBlockProtection
        OIT_SetBlockProtection_PAdminProxy_Rte_NvmBlock_CmnMfgSrv_MfgTmpBuf{0..4}_SetBlockProtection: start-on-event=SetBlockProtection, operation=PAdminProxy_Rte_NvmBlock_CmnMfgSrv_MfgTmpBuf{0..4}.SetBlockProtection
        OIT_SetBlockProtection_PAdminProxy_Rte_NvmBlock_CmnMfgSrv_NxtrMfgEnaCntr_SetBlockProtection: start-on-event=SetBlockProtection, operation=PAdminProxy_Rte_NvmBlock_CmnMfgSrv_NxtrMfgEnaCntr.SetBlockProtection
        OIT_SetBlockProtection_PAdminProxy_Rte_NvmBlock_DiagcMgr_DiagcMgrNtcFltAry_SetBlockProtection: start-on-event=SetBlockProtection, operation=PAdminProxy_Rte_NvmBlock_DiagcMgr_DiagcMgrNtcFltAry.SetBlockProtection
        OIT_SetBlockProtection_PAdminProxy_Rte_NvmBlock_DutyCycThermProtn_FilStVal_SetBlockProtection: start-on-event=SetBlockProtection, operation=PAdminProxy_Rte_NvmBlock_DutyCycThermProtn_FilStVal.SetBlockProtection
        OIT_SetBlockProtection_PAdminProxy_Rte_NvmBlock_EotLrng_EotNvmData_SetBlockProtection: start-on-event=SetBlockProtection, operation=PAdminProxy_Rte_NvmBlock_EotLrng_EotNvmData.SetBlockProtection
        OIT_SetBlockProtection_PAdminProxy_Rte_NvmBlock_HwAg0Meas_HwAg0Offs_SetBlockProtection: start-on-event=SetBlockProtection, operation=PAdminProxy_Rte_NvmBlock_HwAg0Meas_HwAg0Offs.SetBlockProtection
        OIT_SetBlockProtection_PAdminProxy_Rte_NvmBlock_HwAg1Meas_HwAg1Offs_SetBlockProtection: start-on-event=SetBlockProtection, operation=PAdminProxy_Rte_NvmBlock_HwAg1Meas_HwAg1Offs.SetBlockProtection
        OIT_SetBlockProtection_PAdminProxy_Rte_NvmBlock_HwTqCorrln_HwTqChACmnModCmpLpFilSt_SetBlockProtection: start-on-event=SetBlockProtection, operation=PAdminProxy_Rte_NvmBlock_HwTqCorrln_HwTqChACmnModCmpLpFilSt.SetBlockProtection
        OIT_SetBlockProtection_PAdminProxy_Rte_NvmBlock_HwTqCorrln_HwTqChBCmnModCmpLpFilSt_SetBlockProtection: start-on-event=SetBlockProtection, operation=PAdminProxy_Rte_NvmBlock_HwTqCorrln_HwTqChBCmnModCmpLpFilSt.SetBlockProtection
        OIT_SetBlockProtection_PAdminProxy_Rte_NvmBlock_MotAg2Meas_MtrAg2EolPrm_SetBlockProtection: start-on-event=SetBlockProtection, operation=PAdminProxy_Rte_NvmBlock_MotAg2Meas_MtrAg2EolPrm.SetBlockProtection
        OIT_SetBlockProtection_PAdminProxy_Rte_NvmBlock_NvMProxy_NvMProxyClsChkBlk_SetBlockProtection: start-on-event=SetBlockProtection, operation=PAdminProxy_Rte_NvmBlock_NvMProxy_NvMProxyClsChkBlk.SetBlockProtection
        OIT_SetBlockProtection_PAdminProxy_Rte_NvmBlock_PartNr_PartNrBasMdlPartNr_SetBlockProtection: start-on-event=SetBlockProtection, operation=PAdminProxy_Rte_NvmBlock_PartNr_PartNrBasMdlPartNr.SetBlockProtection
        OIT_SetBlockProtection_PAdminProxy_Rte_NvmBlock_PartNr_PartNrCalProgdSts_SetBlockProtection: start-on-event=SetBlockProtection, operation=PAdminProxy_Rte_NvmBlock_PartNr_PartNrCalProgdSts.SetBlockProtection
        OIT_SetBlockProtection_PAdminProxy_Rte_NvmBlock_PartNr_PartNrCcaMfgTrakg_SetBlockProtection: start-on-event=SetBlockProtection, operation=PAdminProxy_Rte_NvmBlock_PartNr_PartNrCcaMfgTrakg.SetBlockProtection
        OIT_SetBlockProtection_PAdminProxy_Rte_NvmBlock_PartNr_PartNrCtrlPidSeedKey_SetBlockProtection: start-on-event=SetBlockProtection, operation=PAdminProxy_Rte_NvmBlock_PartNr_PartNrCtrlPidSeedKey.SetBlockProtection
        OIT_SetBlockProtection_PAdminProxy_Rte_NvmBlock_PartNr_PartNrCustMfgEnaCntr_SetBlockProtection: start-on-event=SetBlockProtection, operation=PAdminProxy_Rte_NvmBlock_PartNr_PartNrCustMfgEnaCntr.SetBlockProtection
        OIT_SetBlockProtection_PAdminProxy_Rte_NvmBlock_PartNr_PartNrDataUniversalNrSysId_SetBlockProtection: start-on-event=SetBlockProtection, operation=PAdminProxy_Rte_NvmBlock_PartNr_PartNrDataUniversalNrSysId.SetBlockProtection
        OIT_SetBlockProtection_PAdminProxy_Rte_NvmBlock_PartNr_PartNrEndMdlPartNr_SetBlockProtection: start-on-event=SetBlockProtection, operation=PAdminProxy_Rte_NvmBlock_PartNr_PartNrEndMdlPartNr.SetBlockProtection
        OIT_SetBlockProtection_PAdminProxy_Rte_NvmBlock_PartNr_PartNrNxtrMfgTrakg_SetBlockProtection: start-on-event=SetBlockProtection, operation=PAdminProxy_Rte_NvmBlock_PartNr_PartNrNxtrMfgTrakg.SetBlockProtection
        OIT_SetBlockProtection_PAdminProxy_Rte_NvmBlock_PartNr_PartNrProgmDate_SetBlockProtection: start-on-event=SetBlockProtection, operation=PAdminProxy_Rte_NvmBlock_PartNr_PartNrProgmDate.SetBlockProtection
        OIT_SetBlockProtection_PAdminProxy_Rte_NvmBlock_PartNr_PartNrProgmSessionSeedKey_SetBlockProtection: start-on-event=SetBlockProtection, operation=PAdminProxy_Rte_NvmBlock_PartNr_PartNrProgmSessionSeedKey.SetBlockProtection
        OIT_SetBlockProtection_PAdminProxy_Rte_NvmBlock_PartNr_PartNrRepairShopCod_SetBlockProtection: start-on-event=SetBlockProtection, operation=PAdminProxy_Rte_NvmBlock_PartNr_PartNrRepairShopCod.SetBlockProtection
        OIT_SetBlockProtection_PAdminProxy_Rte_NvmBlock_PartNr_PartNrSysCodVersNr_SetBlockProtection: start-on-event=SetBlockProtection, operation=PAdminProxy_Rte_NvmBlock_PartNr_PartNrSysCodVersNr.SetBlockProtection
        OIT_SetBlockProtection_PAdminProxy_Rte_NvmBlock_PartNr_PartNrSysName_SetBlockProtection: start-on-event=SetBlockProtection, operation=PAdminProxy_Rte_NvmBlock_PartNr_PartNrSysName.SetBlockProtection
        OIT_SetBlockProtection_PAdminProxy_Rte_NvmBlock_PartNr_PartNrVinData_SetBlockProtection: start-on-event=SetBlockProtection, operation=PAdminProxy_Rte_NvmBlock_PartNr_PartNrVinData.SetBlockProtection
        OIT_SetBlockProtection_PAdminProxy_Rte_NvmBlock_PullCmpActv_PullCmpLongTerm_SetBlockProtection: start-on-event=SetBlockProtection, operation=PAdminProxy_Rte_NvmBlock_PullCmpActv_PullCmpLongTerm.SetBlockProtection
        OIT_SetRamBlockStatus_PSProxy_CurrMeasMotEol_Deprecated_SetRamBlockStatus: start-on-event=SetRamBlockStatus, operation=PSProxy_CurrMeasMotEol_Deprecated.SetRamBlockStatus
        OIT_SetRamBlockStatus_PSProxy_MotPrmNom_SetRamBlockStatus: start-on-event=SetRamBlockStatus, operation=PSProxy_MotPrmNom.SetRamBlockStatus
        OIT_SetRamBlockStatus_PSProxy_PolarityCfgSaved_SetRamBlockStatus: start-on-event=SetRamBlockStatus, operation=PSProxy_PolarityCfgSaved.SetRamBlockStatus
        OIT_SetRamBlockStatus_PSProxy_Rte_NvmBlock_CDD_CurrMeas_CurrMeasEolGainCalSet_SetRamBlockStatus: start-on-event=SetRamBlockStatus, operation=PSProxy_Rte_NvmBlock_CDD_CurrMeas_CurrMeasEolGainCalSet.SetRamBlockStatus
        OIT_SetRamBlockStatus_PSProxy_Rte_NvmBlock_CDD_CurrMeas_CurrMeasEolOffsCalSet_SetRamBlockStatus: start-on-event=SetRamBlockStatus, operation=PSProxy_Rte_NvmBlock_CDD_CurrMeas_CurrMeasEolOffsCalSet.SetRamBlockStatus
        OIT_SetRamBlockStatus_PSProxy_Rte_NvmBlock_CDD_HwTq{0..3}Meas_HwTq{0..3}Offs_SetRamBlockStatus: start-on-event=SetRamBlockStatus, operation=PSProxy_Rte_NvmBlock_CDD_HwTq{0..3}Meas_HwTq{0..3}Offs.SetRamBlockStatus
        OIT_SetRamBlockStatus_PSProxy_Rte_NvmBlock_CDD_MotAg0Meas_MotAg0CoeffTbl_SetRamBlockStatus: start-on-event=SetRamBlockStatus, operation=PSProxy_Rte_NvmBlock_CDD_MotAg0Meas_MotAg0CoeffTbl.SetRamBlockStatus
        OIT_SetRamBlockStatus_PSProxy_Rte_NvmBlock_CDD_MotAg1Meas_MotAg1CoeffTbl_SetRamBlockStatus: start-on-event=SetRamBlockStatus, operation=PSProxy_Rte_NvmBlock_CDD_MotAg1Meas_MotAg1CoeffTbl.SetRamBlockStatus
        OIT_SetRamBlockStatus_PSProxy_Rte_NvmBlock_CDD_MotAgCmp_MotAgCmpMotAgBackEmf_SetRamBlockStatus: start-on-event=SetRamBlockStatus, operation=PSProxy_Rte_NvmBlock_CDD_MotAgCmp_MotAgCmpMotAgBackEmf.SetRamBlockStatus
        OIT_SetRamBlockStatus_PSProxy_Rte_NvmBlock_CmnMfgSrv_CcaHwPartNr_SetRamBlockStatus: start-on-event=SetRamBlockStatus, operation=PSProxy_Rte_NvmBlock_CmnMfgSrv_CcaHwPartNr.SetRamBlockStatus
        OIT_SetRamBlockStatus_PSProxy_Rte_NvmBlock_CmnMfgSrv_CcaSerlNr_SetRamBlockStatus: start-on-event=SetRamBlockStatus, operation=PSProxy_Rte_NvmBlock_CmnMfgSrv_CcaSerlNr.SetRamBlockStatus
        OIT_SetRamBlockStatus_PSProxy_Rte_NvmBlock_CmnMfgSrv_DiRestore_SetRamBlockStatus: start-on-event=SetRamBlockStatus, operation=PSProxy_Rte_NvmBlock_CmnMfgSrv_DiRestore.SetRamBlockStatus
        OIT_SetRamBlockStatus_PSProxy_Rte_NvmBlock_CmnMfgSrv_EpsSysSerlNr_SetRamBlockStatus: start-on-event=SetRamBlockStatus, operation=PSProxy_Rte_NvmBlock_CmnMfgSrv_EpsSysSerlNr.SetRamBlockStatus
        OIT_SetRamBlockStatus_PSProxy_Rte_NvmBlock_CmnMfgSrv_IgnCntr_SetRamBlockStatus: start-on-event=SetRamBlockStatus, operation=PSProxy_Rte_NvmBlock_CmnMfgSrv_IgnCntr.SetRamBlockStatus
        OIT_SetRamBlockStatus_PSProxy_Rte_NvmBlock_CmnMfgSrv_MfgTmpBuf{0..4}_SetRamBlockStatus: start-on-event=SetRamBlockStatus, operation=PSProxy_Rte_NvmBlock_CmnMfgSrv_MfgTmpBuf{0..4}.SetRamBlockStatus
        OIT_SetRamBlockStatus_PSProxy_Rte_NvmBlock_CmnMfgSrv_NxtrMfgEnaCntr_SetRamBlockStatus: start-on-event=SetRamBlockStatus, operation=PSProxy_Rte_NvmBlock_CmnMfgSrv_NxtrMfgEnaCntr.SetRamBlockStatus
        OIT_SetRamBlockStatus_PSProxy_Rte_NvmBlock_DiagcMgr_DiagcMgrNtcFltAry_SetRamBlockStatus: start-on-event=SetRamBlockStatus, operation=PSProxy_Rte_NvmBlock_DiagcMgr_DiagcMgrNtcFltAry.SetRamBlockStatus
        OIT_SetRamBlockStatus_PSProxy_Rte_NvmBlock_DutyCycThermProtn_FilStVal_SetRamBlockStatus: start-on-event=SetRamBlockStatus, operation=PSProxy_Rte_NvmBlock_DutyCycThermProtn_FilStVal.SetRamBlockStatus
        OIT_SetRamBlockStatus_PSProxy_Rte_NvmBlock_EotLrng_EotNvmData_SetRamBlockStatus: start-on-event=SetRamBlockStatus, operation=PSProxy_Rte_NvmBlock_EotLrng_EotNvmData.SetRamBlockStatus
        OIT_SetRamBlockStatus_PSProxy_Rte_NvmBlock_HwAg0Meas_HwAg0Offs_SetRamBlockStatus: start-on-event=SetRamBlockStatus, operation=PSProxy_Rte_NvmBlock_HwAg0Meas_HwAg0Offs.SetRamBlockStatus
        OIT_SetRamBlockStatus_PSProxy_Rte_NvmBlock_HwAg1Meas_HwAg1Offs_SetRamBlockStatus: start-on-event=SetRamBlockStatus, operation=PSProxy_Rte_NvmBlock_HwAg1Meas_HwAg1Offs.SetRamBlockStatus
        OIT_SetRamBlockStatus_PSProxy_Rte_NvmBlock_HwTqCorrln_HwTqChACmnModCmpLpFilSt_SetRamBlockStatus: start-on-event=SetRamBlockStatus, operation=PSProxy_Rte_NvmBlock_HwTqCorrln_HwTqChACmnModCmpLpFilSt.SetRamBlockStatus
        OIT_SetRamBlockStatus_PSProxy_Rte_NvmBlock_HwTqCorrln_HwTqChBCmnModCmpLpFilSt_SetRamBlockStatus: start-on-event=SetRamBlockStatus, operation=PSProxy_Rte_NvmBlock_HwTqCorrln_HwTqChBCmnModCmpLpFilSt.SetRamBlockStatus
        OIT_SetRamBlockStatus_PSProxy_Rte_NvmBlock_MotAg2Meas_MtrAg2EolPrm_SetRamBlockStatus: start-on-event=SetRamBlockStatus, operation=PSProxy_Rte_NvmBlock_MotAg2Meas_MtrAg2EolPrm.SetRamBlockStatus
        OIT_SetRamBlockStatus_PSProxy_Rte_NvmBlock_NvMProxy_NvMProxyClsChkBlk_SetRamBlockStatus: start-on-event=SetRamBlockStatus, operation=PSProxy_Rte_NvmBlock_NvMProxy_NvMProxyClsChkBlk.SetRamBlockStatus
        OIT_SetRamBlockStatus_PSProxy_Rte_NvmBlock_PartNr_PartNrBasMdlPartNr_SetRamBlockStatus: start-on-event=SetRamBlockStatus, operation=PSProxy_Rte_NvmBlock_PartNr_PartNrBasMdlPartNr.SetRamBlockStatus
        OIT_SetRamBlockStatus_PSProxy_Rte_NvmBlock_PartNr_PartNrCalProgdSts_SetRamBlockStatus: start-on-event=SetRamBlockStatus, operation=PSProxy_Rte_NvmBlock_PartNr_PartNrCalProgdSts.SetRamBlockStatus
        OIT_SetRamBlockStatus_PSProxy_Rte_NvmBlock_PartNr_PartNrCcaMfgTrakg_SetRamBlockStatus: start-on-event=SetRamBlockStatus, operation=PSProxy_Rte_NvmBlock_PartNr_PartNrCcaMfgTrakg.SetRamBlockStatus
        OIT_SetRamBlockStatus_PSProxy_Rte_NvmBlock_PartNr_PartNrCtrlPidSeedKey_SetRamBlockStatus: start-on-event=SetRamBlockStatus, operation=PSProxy_Rte_NvmBlock_PartNr_PartNrCtrlPidSeedKey.SetRamBlockStatus
        OIT_SetRamBlockStatus_PSProxy_Rte_NvmBlock_PartNr_PartNrCustMfgEnaCntr_SetRamBlockStatus: start-on-event=SetRamBlockStatus, operation=PSProxy_Rte_NvmBlock_PartNr_PartNrCustMfgEnaCntr.SetRamBlockStatus
        OIT_SetRamBlockStatus_PSProxy_Rte_NvmBlock_PartNr_PartNrDataUniversalNrSysId_SetRamBlockStatus: start-on-event=SetRamBlockStatus, operation=PSProxy_Rte_NvmBlock_PartNr_PartNrDataUniversalNrSysId.SetRamBlockStatus
        OIT_SetRamBlockStatus_PSProxy_Rte_NvmBlock_PartNr_PartNrEndMdlPartNr_SetRamBlockStatus: start-on-event=SetRamBlockStatus, operation=PSProxy_Rte_NvmBlock_PartNr_PartNrEndMdlPartNr.SetRamBlockStatus
        OIT_SetRamBlockStatus_PSProxy_Rte_NvmBlock_PartNr_PartNrNxtrMfgTrakg_SetRamBlockStatus: start-on-event=SetRamBlockStatus, operation=PSProxy_Rte_NvmBlock_PartNr_PartNrNxtrMfgTrakg.SetRamBlockStatus
        OIT_SetRamBlockStatus_PSProxy_Rte_NvmBlock_PartNr_PartNrProgmDate_SetRamBlockStatus: start-on-event=SetRamBlockStatus, operation=PSProxy_Rte_NvmBlock_PartNr_PartNrProgmDate.SetRamBlockStatus
        OIT_SetRamBlockStatus_PSProxy_Rte_NvmBlock_PartNr_PartNrProgmSessionSeedKey_SetRamBlockStatus: start-on-event=SetRamBlockStatus, operation=PSProxy_Rte_NvmBlock_PartNr_PartNrProgmSessionSeedKey.SetRamBlockStatus
        OIT_SetRamBlockStatus_PSProxy_Rte_NvmBlock_PartNr_PartNrRepairShopCod_SetRamBlockStatus: start-on-event=SetRamBlockStatus, operation=PSProxy_Rte_NvmBlock_PartNr_PartNrRepairShopCod.SetRamBlockStatus
        OIT_SetRamBlockStatus_PSProxy_Rte_NvmBlock_PartNr_PartNrSysCodVersNr_SetRamBlockStatus: start-on-event=SetRamBlockStatus, operation=PSProxy_Rte_NvmBlock_PartNr_PartNrSysCodVersNr.SetRamBlockStatus
        OIT_SetRamBlockStatus_PSProxy_Rte_NvmBlock_PartNr_PartNrSysName_SetRamBlockStatus: start-on-event=SetRamBlockStatus, operation=PSProxy_Rte_NvmBlock_PartNr_PartNrSysName.SetRamBlockStatus
        OIT_SetRamBlockStatus_PSProxy_Rte_NvmBlock_PartNr_PartNrVinData_SetRamBlockStatus: start-on-event=SetRamBlockStatus, operation=PSProxy_Rte_NvmBlock_PartNr_PartNrVinData.SetRamBlockStatus
        OIT_SetRamBlockStatus_PSProxy_Rte_NvmBlock_PullCmpActv_PullCmpLongTerm_SetRamBlockStatus: start-on-event=SetRamBlockStatus, operation=PSProxy_Rte_NvmBlock_PullCmpActv_PullCmpLongTerm.SetRamBlockStatus
        OIT_WriteBlock_PSProxy_CurrMeasMotEol_Deprecated_WriteBlock: start-on-event=WriteBlock, operation=PSProxy_CurrMeasMotEol_Deprecated.WriteBlock
        OIT_WriteBlock_PSProxy_MotPrmNom_WriteBlock: start-on-event=WriteBlock, operation=PSProxy_MotPrmNom.WriteBlock
        OIT_WriteBlock_PSProxy_PolarityCfgSaved_WriteBlock: start-on-event=WriteBlock, operation=PSProxy_PolarityCfgSaved.WriteBlock
        OIT_WriteBlock_PSProxy_Rte_NvmBlock_CDD_CurrMeas_CurrMeasEolGainCalSet_WriteBlock: start-on-event=WriteBlock, operation=PSProxy_Rte_NvmBlock_CDD_CurrMeas_CurrMeasEolGainCalSet.WriteBlock
        OIT_WriteBlock_PSProxy_Rte_NvmBlock_CDD_CurrMeas_CurrMeasEolOffsCalSet_WriteBlock: start-on-event=WriteBlock, operation=PSProxy_Rte_NvmBlock_CDD_CurrMeas_CurrMeasEolOffsCalSet.WriteBlock
        OIT_WriteBlock_PSProxy_Rte_NvmBlock_CDD_HwTq{0..3}Meas_HwTq{0..3}Offs_WriteBlock: start-on-event=WriteBlock, operation=PSProxy_Rte_NvmBlock_CDD_HwTq{0..3}Meas_HwTq{0..3}Offs.WriteBlock
        OIT_WriteBlock_PSProxy_Rte_NvmBlock_CDD_MotAg0Meas_MotAg0CoeffTbl_WriteBlock: start-on-event=WriteBlock, operation=PSProxy_Rte_NvmBlock_CDD_MotAg0Meas_MotAg0CoeffTbl.WriteBlock
        OIT_WriteBlock_PSProxy_Rte_NvmBlock_CDD_MotAg1Meas_MotAg1CoeffTbl_WriteBlock: start-on-event=WriteBlock, operation=PSProxy_Rte_NvmBlock_CDD_MotAg1Meas_MotAg1CoeffTbl.WriteBlock
        OIT_WriteBlock_PSProxy_Rte_NvmBlock_CDD_MotAgCmp_MotAgCmpMotAgBackEmf_WriteBlock: start-on-event=WriteBlock, operation=PSProxy_Rte_NvmBlock_CDD_MotAgCmp_MotAgCmpMotAgBackEmf.WriteBlock
        OIT_WriteBlock_PSProxy_Rte_NvmBlock_CmnMfgSrv_CcaHwPartNr_WriteBlock: start-on-event=WriteBlock, operation=PSProxy_Rte_NvmBlock_CmnMfgSrv_CcaHwPartNr.WriteBlock
        OIT_WriteBlock_PSProxy_Rte_NvmBlock_CmnMfgSrv_CcaSerlNr_WriteBlock: start-on-event=WriteBlock, operation=PSProxy_Rte_NvmBlock_CmnMfgSrv_CcaSerlNr.WriteBlock
        OIT_WriteBlock_PSProxy_Rte_NvmBlock_CmnMfgSrv_DiRestore_WriteBlock: start-on-event=WriteBlock, operation=PSProxy_Rte_NvmBlock_CmnMfgSrv_DiRestore.WriteBlock
        OIT_WriteBlock_PSProxy_Rte_NvmBlock_CmnMfgSrv_EpsSysSerlNr_WriteBlock: start-on-event=WriteBlock, operation=PSProxy_Rte_NvmBlock_CmnMfgSrv_EpsSysSerlNr.WriteBlock
        OIT_WriteBlock_PSProxy_Rte_NvmBlock_CmnMfgSrv_IgnCntr_WriteBlock: start-on-event=WriteBlock, operation=PSProxy_Rte_NvmBlock_CmnMfgSrv_IgnCntr.WriteBlock
        OIT_WriteBlock_PSProxy_Rte_NvmBlock_CmnMfgSrv_MfgTmpBuf{0..4}_WriteBlock: start-on-event=WriteBlock, operation=PSProxy_Rte_NvmBlock_CmnMfgSrv_MfgTmpBuf{0..4}.WriteBlock
        OIT_WriteBlock_PSProxy_Rte_NvmBlock_CmnMfgSrv_NxtrMfgEnaCntr_WriteBlock: start-on-event=WriteBlock, operation=PSProxy_Rte_NvmBlock_CmnMfgSrv_NxtrMfgEnaCntr.WriteBlock
        OIT_WriteBlock_PSProxy_Rte_NvmBlock_DiagcMgr_DiagcMgrNtcFltAry_WriteBlock: start-on-event=WriteBlock, operation=PSProxy_Rte_NvmBlock_DiagcMgr_DiagcMgrNtcFltAry.WriteBlock
        OIT_WriteBlock_PSProxy_Rte_NvmBlock_DutyCycThermProtn_FilStVal_WriteBlock: start-on-event=WriteBlock, operation=PSProxy_Rte_NvmBlock_DutyCycThermProtn_FilStVal.WriteBlock
        OIT_WriteBlock_PSProxy_Rte_NvmBlock_EotLrng_EotNvmData_WriteBlock: start-on-event=WriteBlock, operation=PSProxy_Rte_NvmBlock_EotLrng_EotNvmData.WriteBlock
        OIT_WriteBlock_PSProxy_Rte_NvmBlock_HwAg0Meas_HwAg0Offs_WriteBlock: start-on-event=WriteBlock, operation=PSProxy_Rte_NvmBlock_HwAg0Meas_HwAg0Offs.WriteBlock
        OIT_WriteBlock_PSProxy_Rte_NvmBlock_HwAg1Meas_HwAg1Offs_WriteBlock: start-on-event=WriteBlock, operation=PSProxy_Rte_NvmBlock_HwAg1Meas_HwAg1Offs.WriteBlock
        OIT_WriteBlock_PSProxy_Rte_NvmBlock_HwTqCorrln_HwTqChACmnModCmpLpFilSt_WriteBlock: start-on-event=WriteBlock, operation=PSProxy_Rte_NvmBlock_HwTqCorrln_HwTqChACmnModCmpLpFilSt.WriteBlock
        OIT_WriteBlock_PSProxy_Rte_NvmBlock_HwTqCorrln_HwTqChBCmnModCmpLpFilSt_WriteBlock: start-on-event=WriteBlock, operation=PSProxy_Rte_NvmBlock_HwTqCorrln_HwTqChBCmnModCmpLpFilSt.WriteBlock
        OIT_WriteBlock_PSProxy_Rte_NvmBlock_MotAg2Meas_MtrAg2EolPrm_WriteBlock: start-on-event=WriteBlock, operation=PSProxy_Rte_NvmBlock_MotAg2Meas_MtrAg2EolPrm.WriteBlock
        OIT_WriteBlock_PSProxy_Rte_NvmBlock_NvMProxy_NvMProxyClsChkBlk_WriteBlock: start-on-event=WriteBlock, operation=PSProxy_Rte_NvmBlock_NvMProxy_NvMProxyClsChkBlk.WriteBlock
        OIT_WriteBlock_PSProxy_Rte_NvmBlock_PartNr_PartNrBasMdlPartNr_WriteBlock: start-on-event=WriteBlock, operation=PSProxy_Rte_NvmBlock_PartNr_PartNrBasMdlPartNr.WriteBlock
        OIT_WriteBlock_PSProxy_Rte_NvmBlock_PartNr_PartNrCalProgdSts_WriteBlock: start-on-event=WriteBlock, operation=PSProxy_Rte_NvmBlock_PartNr_PartNrCalProgdSts.WriteBlock
        OIT_WriteBlock_PSProxy_Rte_NvmBlock_PartNr_PartNrCcaMfgTrakg_WriteBlock: start-on-event=WriteBlock, operation=PSProxy_Rte_NvmBlock_PartNr_PartNrCcaMfgTrakg.WriteBlock
        OIT_WriteBlock_PSProxy_Rte_NvmBlock_PartNr_PartNrCtrlPidSeedKey_WriteBlock: start-on-event=WriteBlock, operation=PSProxy_Rte_NvmBlock_PartNr_PartNrCtrlPidSeedKey.WriteBlock
        OIT_WriteBlock_PSProxy_Rte_NvmBlock_PartNr_PartNrCustMfgEnaCntr_WriteBlock: start-on-event=WriteBlock, operation=PSProxy_Rte_NvmBlock_PartNr_PartNrCustMfgEnaCntr.WriteBlock
        OIT_WriteBlock_PSProxy_Rte_NvmBlock_PartNr_PartNrDataUniversalNrSysId_WriteBlock: start-on-event=WriteBlock, operation=PSProxy_Rte_NvmBlock_PartNr_PartNrDataUniversalNrSysId.WriteBlock
        OIT_WriteBlock_PSProxy_Rte_NvmBlock_PartNr_PartNrEndMdlPartNr_WriteBlock: start-on-event=WriteBlock, operation=PSProxy_Rte_NvmBlock_PartNr_PartNrEndMdlPartNr.WriteBlock
        OIT_WriteBlock_PSProxy_Rte_NvmBlock_PartNr_PartNrNxtrMfgTrakg_WriteBlock: start-on-event=WriteBlock, operation=PSProxy_Rte_NvmBlock_PartNr_PartNrNxtrMfgTrakg.WriteBlock
        OIT_WriteBlock_PSProxy_Rte_NvmBlock_PartNr_PartNrProgmDate_WriteBlock: start-on-event=WriteBlock, operation=PSProxy_Rte_NvmBlock_PartNr_PartNrProgmDate.WriteBlock
        OIT_WriteBlock_PSProxy_Rte_NvmBlock_PartNr_PartNrProgmSessionSeedKey_WriteBlock: start-on-event=WriteBlock, operation=PSProxy_Rte_NvmBlock_PartNr_PartNrProgmSessionSeedKey.WriteBlock
        OIT_WriteBlock_PSProxy_Rte_NvmBlock_PartNr_PartNrRepairShopCod_WriteBlock: start-on-event=WriteBlock, operation=PSProxy_Rte_NvmBlock_PartNr_PartNrRepairShopCod.WriteBlock
        OIT_WriteBlock_PSProxy_Rte_NvmBlock_PartNr_PartNrSysCodVersNr_WriteBlock: start-on-event=WriteBlock, operation=PSProxy_Rte_NvmBlock_PartNr_PartNrSysCodVersNr.WriteBlock
        OIT_WriteBlock_PSProxy_Rte_NvmBlock_PartNr_PartNrSysName_WriteBlock: start-on-event=WriteBlock, operation=PSProxy_Rte_NvmBlock_PartNr_PartNrSysName.WriteBlock
        OIT_WriteBlock_PSProxy_Rte_NvmBlock_PartNr_PartNrVinData_WriteBlock: start-on-event=WriteBlock, operation=PSProxy_Rte_NvmBlock_PartNr_PartNrVinData.WriteBlock
        OIT_WriteBlock_PSProxy_Rte_NvmBlock_PullCmpActv_PullCmpLongTerm_WriteBlock: start-on-event=WriteBlock, operation=PSProxy_Rte_NvmBlock_PullCmpActv_PullCmpLongTerm.WriteBlock
      port-api-options:
        {enable-take-address=true, indirect-api=false, port-defined-argument-value{value=PAdminProxy_CurrMeasMotEol_Deprecated_0:2, value-type=NvM_BlockIdType}, port=PAdminProxy_CurrMeasMotEol_Deprecated}
        {enable-take-address=true, indirect-api=false, port-defined-argument-value{value=PAdminProxy_MotPrmNom_0:45, value-type=NvM_BlockIdType}, port=PAdminProxy_MotPrmNom}
        {enable-take-address=true, indirect-api=false, port-defined-argument-value{value=PAdminProxy_PolarityCfgSaved_0:48, value-type=NvM_BlockIdType}, port=PAdminProxy_PolarityCfgSaved}
        {enable-take-address=true, indirect-api=false, port-defined-argument-value{value=PAdminProxy_Rte_NvmBlock_CDD_CurrMeas_CurrMeasEolGainCalSet_0:28, value-type=NvM_BlockIdType}, port=PAdminProxy_Rte_NvmBlock_CDD_CurrMeas_CurrMeasEolGainCalSet}
        {enable-take-address=true, indirect-api=false, port-defined-argument-value{value=PAdminProxy_Rte_NvmBlock_CDD_CurrMeas_CurrMeasEolOffsCalSet_0:29, value-type=NvM_BlockIdType}, port=PAdminProxy_Rte_NvmBlock_CDD_CurrMeas_CurrMeasEolOffsCalSet}
        {enable-take-address=true, indirect-api=false, port-defined-argument-value{value=PAdminProxy_Rte_NvmBlock_CDD_HwTq0Meas_HwTq0Offs_0:33, value-type=NvM_BlockIdType}, port=PAdminProxy_Rte_NvmBlock_CDD_HwTq0Meas_HwTq0Offs}
        {enable-take-address=true, indirect-api=false, port-defined-argument-value{value=PAdminProxy_Rte_NvmBlock_CDD_HwTq1Meas_HwTq1Offs_0:34, value-type=NvM_BlockIdType}, port=PAdminProxy_Rte_NvmBlock_CDD_HwTq1Meas_HwTq1Offs}
        {enable-take-address=true, indirect-api=false, port-defined-argument-value{value=PAdminProxy_Rte_NvmBlock_CDD_HwTq2Meas_HwTq2Offs_0:36, value-type=NvM_BlockIdType}, port=PAdminProxy_Rte_NvmBlock_CDD_HwTq2Meas_HwTq2Offs}
        {enable-take-address=true, indirect-api=false, port-defined-argument-value{value=PAdminProxy_Rte_NvmBlock_CDD_HwTq3Meas_HwTq3Offs_0:35, value-type=NvM_BlockIdType}, port=PAdminProxy_Rte_NvmBlock_CDD_HwTq3Meas_HwTq3Offs}
        {enable-take-address=true, indirect-api=false, port-defined-argument-value{value=PAdminProxy_Rte_NvmBlock_CDD_MotAg0Meas_MotAg0CoeffTbl_0:47, value-type=NvM_BlockIdType}, port=PAdminProxy_Rte_NvmBlock_CDD_MotAg0Meas_MotAg0CoeffTbl}
        {enable-take-address=true, indirect-api=false, port-defined-argument-value{value=PAdminProxy_Rte_NvmBlock_CDD_MotAg1Meas_MotAg1CoeffTbl_0:42, value-type=NvM_BlockIdType}, port=PAdminProxy_Rte_NvmBlock_CDD_MotAg1Meas_MotAg1CoeffTbl}
        {enable-take-address=true, indirect-api=false, port-defined-argument-value{value=PAdminProxy_Rte_NvmBlock_CDD_MotAgCmp_MotAgCmpMotAgBackEmf_0:46, value-type=NvM_BlockIdType}, port=PAdminProxy_Rte_NvmBlock_CDD_MotAgCmp_MotAgCmpMotAgBackEmf}
        {enable-take-address=true, indirect-api=false, port-defined-argument-value{value=PAdminProxy_Rte_NvmBlock_CmnMfgSrv_CcaHwPartNr_0:11, value-type=NvM_BlockIdType}, port=PAdminProxy_Rte_NvmBlock_CmnMfgSrv_CcaHwPartNr}
        {enable-take-address=true, indirect-api=false, port-defined-argument-value{value=PAdminProxy_Rte_NvmBlock_CmnMfgSrv_CcaSerlNr_0:13, value-type=NvM_BlockIdType}, port=PAdminProxy_Rte_NvmBlock_CmnMfgSrv_CcaSerlNr}
        {enable-take-address=true, indirect-api=false, port-defined-argument-value{value=PAdminProxy_Rte_NvmBlock_CmnMfgSrv_DiRestore_0:8, value-type=NvM_BlockIdType}, port=PAdminProxy_Rte_NvmBlock_CmnMfgSrv_DiRestore}
        {enable-take-address=true, indirect-api=false, port-defined-argument-value{value=PAdminProxy_Rte_NvmBlock_CmnMfgSrv_EpsSysSerlNr_0:6, value-type=NvM_BlockIdType}, port=PAdminProxy_Rte_NvmBlock_CmnMfgSrv_EpsSysSerlNr}
        {enable-take-address=true, indirect-api=false, port-defined-argument-value{value=PAdminProxy_Rte_NvmBlock_CmnMfgSrv_IgnCntr_0:44, value-type=NvM_BlockIdType}, port=PAdminProxy_Rte_NvmBlock_CmnMfgSrv_IgnCntr}
        {enable-take-address=true, indirect-api=false, port-defined-argument-value{value=PAdminProxy_Rte_NvmBlock_CmnMfgSrv_MfgTmpBuf0_0:12, value-type=NvM_BlockIdType}, port=PAdminProxy_Rte_NvmBlock_CmnMfgSrv_MfgTmpBuf0}
        {enable-take-address=true, indirect-api=false, port-defined-argument-value{value=PAdminProxy_Rte_NvmBlock_CmnMfgSrv_MfgTmpBuf1_0:10, value-type=NvM_BlockIdType}, port=PAdminProxy_Rte_NvmBlock_CmnMfgSrv_MfgTmpBuf1}
        {enable-take-address=true, indirect-api=false, port-defined-argument-value{value=PAdminProxy_Rte_NvmBlock_CmnMfgSrv_MfgTmpBuf2_0:9, value-type=NvM_BlockIdType}, port=PAdminProxy_Rte_NvmBlock_CmnMfgSrv_MfgTmpBuf2}
        {enable-take-address=true, indirect-api=false, port-defined-argument-value{value=PAdminProxy_Rte_NvmBlock_CmnMfgSrv_MfgTmpBuf3_0:7, value-type=NvM_BlockIdType}, port=PAdminProxy_Rte_NvmBlock_CmnMfgSrv_MfgTmpBuf3}
        {enable-take-address=true, indirect-api=false, port-defined-argument-value{value=PAdminProxy_Rte_NvmBlock_CmnMfgSrv_MfgTmpBuf4_0:5, value-type=NvM_BlockIdType}, port=PAdminProxy_Rte_NvmBlock_CmnMfgSrv_MfgTmpBuf4}
        {enable-take-address=true, indirect-api=false, port-defined-argument-value{value=PAdminProxy_Rte_NvmBlock_CmnMfgSrv_NxtrMfgEnaCntr_0:43, value-type=NvM_BlockIdType}, port=PAdminProxy_Rte_NvmBlock_CmnMfgSrv_NxtrMfgEnaCntr}
        {enable-take-address=true, indirect-api=false, port-defined-argument-value{value=PAdminProxy_Rte_NvmBlock_DiagcMgr_DiagcMgrNtcFltAry_0:31, value-type=NvM_BlockIdType}, port=PAdminProxy_Rte_NvmBlock_DiagcMgr_DiagcMgrNtcFltAry}
        {enable-take-address=true, indirect-api=false, port-defined-argument-value{value=PAdminProxy_Rte_NvmBlock_DutyCycThermProtn_FilStVal_0:4, value-type=NvM_BlockIdType}, port=PAdminProxy_Rte_NvmBlock_DutyCycThermProtn_FilStVal}
        {enable-take-address=true, indirect-api=false, port-defined-argument-value{value=PAdminProxy_Rte_NvmBlock_EotLrng_EotNvmData_0:30, value-type=NvM_BlockIdType}, port=PAdminProxy_Rte_NvmBlock_EotLrng_EotNvmData}
        {enable-take-address=true, indirect-api=false, port-defined-argument-value{value=PAdminProxy_Rte_NvmBlock_HwAg0Meas_HwAg0Offs_0:41, value-type=NvM_BlockIdType}, port=PAdminProxy_Rte_NvmBlock_HwAg0Meas_HwAg0Offs}
        {enable-take-address=true, indirect-api=false, port-defined-argument-value{value=PAdminProxy_Rte_NvmBlock_HwAg1Meas_HwAg1Offs_0:39, value-type=NvM_BlockIdType}, port=PAdminProxy_Rte_NvmBlock_HwAg1Meas_HwAg1Offs}
        {enable-take-address=true, indirect-api=false, port-defined-argument-value{value=PAdminProxy_Rte_NvmBlock_HwTqCorrln_HwTqChACmnModCmpLpFilSt_0:37, value-type=NvM_BlockIdType}, port=PAdminProxy_Rte_NvmBlock_HwTqCorrln_HwTqChACmnModCmpLpFilSt}
        {enable-take-address=true, indirect-api=false, port-defined-argument-value{value=PAdminProxy_Rte_NvmBlock_HwTqCorrln_HwTqChBCmnModCmpLpFilSt_0:38, value-type=NvM_BlockIdType}, port=PAdminProxy_Rte_NvmBlock_HwTqCorrln_HwTqChBCmnModCmpLpFilSt}
        {enable-take-address=true, indirect-api=false, port-defined-argument-value{value=PAdminProxy_Rte_NvmBlock_MotAg2Meas_MtrAg2EolPrm_0:32, value-type=NvM_BlockIdType}, port=PAdminProxy_Rte_NvmBlock_MotAg2Meas_MtrAg2EolPrm}
        {enable-take-address=true, indirect-api=false, port-defined-argument-value{value=PAdminProxy_Rte_NvmBlock_NvMProxy_NvMProxyClsChkBlk_0:40, value-type=NvM_BlockIdType}, port=PAdminProxy_Rte_NvmBlock_NvMProxy_NvMProxyClsChkBlk}
        {enable-take-address=true, indirect-api=false, port-defined-argument-value{value=PAdminProxy_Rte_NvmBlock_PartNr_PartNrBasMdlPartNr_0:20, value-type=NvM_BlockIdType}, port=PAdminProxy_Rte_NvmBlock_PartNr_PartNrBasMdlPartNr}
        {enable-take-address=true, indirect-api=false, port-defined-argument-value{value=PAdminProxy_Rte_NvmBlock_PartNr_PartNrCalProgdSts_0:25, value-type=NvM_BlockIdType}, port=PAdminProxy_Rte_NvmBlock_PartNr_PartNrCalProgdSts}
        {enable-take-address=true, indirect-api=false, port-defined-argument-value{value=PAdminProxy_Rte_NvmBlock_PartNr_PartNrCcaMfgTrakg_0:16, value-type=NvM_BlockIdType}, port=PAdminProxy_Rte_NvmBlock_PartNr_PartNrCcaMfgTrakg}
        {enable-take-address=true, indirect-api=false, port-defined-argument-value{value=PAdminProxy_Rte_NvmBlock_PartNr_PartNrCtrlPidSeedKey_0:21, value-type=NvM_BlockIdType}, port=PAdminProxy_Rte_NvmBlock_PartNr_PartNrCtrlPidSeedKey}
        {enable-take-address=true, indirect-api=false, port-defined-argument-value{value=PAdminProxy_Rte_NvmBlock_PartNr_PartNrCustMfgEnaCntr_0:26, value-type=NvM_BlockIdType}, port=PAdminProxy_Rte_NvmBlock_PartNr_PartNrCustMfgEnaCntr}
        {enable-take-address=true, indirect-api=false, port-defined-argument-value{value=PAdminProxy_Rte_NvmBlock_PartNr_PartNrDataUniversalNrSysId_0:24, value-type=NvM_BlockIdType}, port=PAdminProxy_Rte_NvmBlock_PartNr_PartNrDataUniversalNrSysId}
        {enable-take-address=true, indirect-api=false, port-defined-argument-value{value=PAdminProxy_Rte_NvmBlock_PartNr_PartNrEndMdlPartNr_0:19, value-type=NvM_BlockIdType}, port=PAdminProxy_Rte_NvmBlock_PartNr_PartNrEndMdlPartNr}
        {enable-take-address=true, indirect-api=false, port-defined-argument-value{value=PAdminProxy_Rte_NvmBlock_PartNr_PartNrNxtrMfgTrakg_0:18, value-type=NvM_BlockIdType}, port=PAdminProxy_Rte_NvmBlock_PartNr_PartNrNxtrMfgTrakg}
        {enable-take-address=true, indirect-api=false, port-defined-argument-value{value=PAdminProxy_Rte_NvmBlock_PartNr_PartNrProgmDate_0:23, value-type=NvM_BlockIdType}, port=PAdminProxy_Rte_NvmBlock_PartNr_PartNrProgmDate}
        {enable-take-address=true, indirect-api=false, port-defined-argument-value{value=PAdminProxy_Rte_NvmBlock_PartNr_PartNrProgmSessionSeedKey_0:27, value-type=NvM_BlockIdType}, port=PAdminProxy_Rte_NvmBlock_PartNr_PartNrProgmSessionSeedKey}
        {enable-take-address=true, indirect-api=false, port-defined-argument-value{value=PAdminProxy_Rte_NvmBlock_PartNr_PartNrRepairShopCod_0:14, value-type=NvM_BlockIdType}, port=PAdminProxy_Rte_NvmBlock_PartNr_PartNrRepairShopCod}
        {enable-take-address=true, indirect-api=false, port-defined-argument-value{value=PAdminProxy_Rte_NvmBlock_PartNr_PartNrSysCodVersNr_0:17, value-type=NvM_BlockIdType}, port=PAdminProxy_Rte_NvmBlock_PartNr_PartNrSysCodVersNr}
        {enable-take-address=true, indirect-api=false, port-defined-argument-value{value=PAdminProxy_Rte_NvmBlock_PartNr_PartNrSysName_0:15, value-type=NvM_BlockIdType}, port=PAdminProxy_Rte_NvmBlock_PartNr_PartNrSysName}
        {enable-take-address=true, indirect-api=false, port-defined-argument-value{value=PAdminProxy_Rte_NvmBlock_PartNr_PartNrVinData_0:22, value-type=NvM_BlockIdType}, port=PAdminProxy_Rte_NvmBlock_PartNr_PartNrVinData}
        {enable-take-address=true, indirect-api=false, port-defined-argument-value{value=PAdminProxy_Rte_NvmBlock_PullCmpActv_PullCmpLongTerm_0:3, value-type=NvM_BlockIdType}, port=PAdminProxy_Rte_NvmBlock_PullCmpActv_PullCmpLongTerm}
        {enable-take-address=false, indirect-api=false, port-defined-argument-value{value=PSProxy_CurrMeasMotEol_Deprecated_0:2, value-type=NvM_BlockIdType}, port=PSProxy_CurrMeasMotEol_Deprecated}
        {enable-take-address=false, indirect-api=false, port-defined-argument-value{value=PSProxy_MotPrmNom_0:45, value-type=NvM_BlockIdType}, port=PSProxy_MotPrmNom}
        {enable-take-address=false, indirect-api=false, port-defined-argument-value{value=PSProxy_PolarityCfgSaved_0:48, value-type=NvM_BlockIdType}, port=PSProxy_PolarityCfgSaved}
        {enable-take-address=false, indirect-api=false, port-defined-argument-value{value=PSProxy_Rte_NvmBlock_CDD_CurrMeas_CurrMeasEolGainCalSet_0:28, value-type=NvM_BlockIdType}, port=PSProxy_Rte_NvmBlock_CDD_CurrMeas_CurrMeasEolGainCalSet}
        {enable-take-address=false, indirect-api=false, port-defined-argument-value{value=PSProxy_Rte_NvmBlock_CDD_CurrMeas_CurrMeasEolOffsCalSet_0:29, value-type=NvM_BlockIdType}, port=PSProxy_Rte_NvmBlock_CDD_CurrMeas_CurrMeasEolOffsCalSet}
        {enable-take-address=false, indirect-api=false, port-defined-argument-value{value=PSProxy_Rte_NvmBlock_CDD_HwTq0Meas_HwTq0Offs_0:33, value-type=NvM_BlockIdType}, port=PSProxy_Rte_NvmBlock_CDD_HwTq0Meas_HwTq0Offs}
        {enable-take-address=false, indirect-api=false, port-defined-argument-value{value=PSProxy_Rte_NvmBlock_CDD_HwTq1Meas_HwTq1Offs_0:34, value-type=NvM_BlockIdType}, port=PSProxy_Rte_NvmBlock_CDD_HwTq1Meas_HwTq1Offs}
        {enable-take-address=false, indirect-api=false, port-defined-argument-value{value=PSProxy_Rte_NvmBlock_CDD_HwTq2Meas_HwTq2Offs_0:36, value-type=NvM_BlockIdType}, port=PSProxy_Rte_NvmBlock_CDD_HwTq2Meas_HwTq2Offs}
        {enable-take-address=false, indirect-api=false, port-defined-argument-value{value=PSProxy_Rte_NvmBlock_CDD_HwTq3Meas_HwTq3Offs_0:35, value-type=NvM_BlockIdType}, port=PSProxy_Rte_NvmBlock_CDD_HwTq3Meas_HwTq3Offs}
        {enable-take-address=false, indirect-api=false, port-defined-argument-value{value=PSProxy_Rte_NvmBlock_CDD_MotAg0Meas_MotAg0CoeffTbl_0:47, value-type=NvM_BlockIdType}, port=PSProxy_Rte_NvmBlock_CDD_MotAg0Meas_MotAg0CoeffTbl}
        {enable-take-address=false, indirect-api=false, port-defined-argument-value{value=PSProxy_Rte_NvmBlock_CDD_MotAg1Meas_MotAg1CoeffTbl_0:42, value-type=NvM_BlockIdType}, port=PSProxy_Rte_NvmBlock_CDD_MotAg1Meas_MotAg1CoeffTbl}
        {enable-take-address=false, indirect-api=false, port-defined-argument-value{value=PSProxy_Rte_NvmBlock_CDD_MotAgCmp_MotAgCmpMotAgBackEmf_0:46, value-type=NvM_BlockIdType}, port=PSProxy_Rte_NvmBlock_CDD_MotAgCmp_MotAgCmpMotAgBackEmf}
        {enable-take-address=false, indirect-api=false, port-defined-argument-value{value=PSProxy_Rte_NvmBlock_CmnMfgSrv_CcaHwPartNr_0:11, value-type=NvM_BlockIdType}, port=PSProxy_Rte_NvmBlock_CmnMfgSrv_CcaHwPartNr}
        {enable-take-address=false, indirect-api=false, port-defined-argument-value{value=PSProxy_Rte_NvmBlock_CmnMfgSrv_CcaSerlNr_0:13, value-type=NvM_BlockIdType}, port=PSProxy_Rte_NvmBlock_CmnMfgSrv_CcaSerlNr}
        {enable-take-address=false, indirect-api=false, port-defined-argument-value{value=PSProxy_Rte_NvmBlock_CmnMfgSrv_DiRestore_0:8, value-type=NvM_BlockIdType}, port=PSProxy_Rte_NvmBlock_CmnMfgSrv_DiRestore}
        {enable-take-address=false, indirect-api=false, port-defined-argument-value{value=PSProxy_Rte_NvmBlock_CmnMfgSrv_EpsSysSerlNr_0:6, value-type=NvM_BlockIdType}, port=PSProxy_Rte_NvmBlock_CmnMfgSrv_EpsSysSerlNr}
        {enable-take-address=false, indirect-api=false, port-defined-argument-value{value=PSProxy_Rte_NvmBlock_CmnMfgSrv_IgnCntr_0:44, value-type=NvM_BlockIdType}, port=PSProxy_Rte_NvmBlock_CmnMfgSrv_IgnCntr}
        {enable-take-address=false, indirect-api=false, port-defined-argument-value{value=PSProxy_Rte_NvmBlock_CmnMfgSrv_MfgTmpBuf0_0:12, value-type=NvM_BlockIdType}, port=PSProxy_Rte_NvmBlock_CmnMfgSrv_MfgTmpBuf0}
        {enable-take-address=false, indirect-api=false, port-defined-argument-value{value=PSProxy_Rte_NvmBlock_CmnMfgSrv_MfgTmpBuf1_0:10, value-type=NvM_BlockIdType}, port=PSProxy_Rte_NvmBlock_CmnMfgSrv_MfgTmpBuf1}
        {enable-take-address=false, indirect-api=false, port-defined-argument-value{value=PSProxy_Rte_NvmBlock_CmnMfgSrv_MfgTmpBuf2_0:9, value-type=NvM_BlockIdType}, port=PSProxy_Rte_NvmBlock_CmnMfgSrv_MfgTmpBuf2}
        {enable-take-address=false, indirect-api=false, port-defined-argument-value{value=PSProxy_Rte_NvmBlock_CmnMfgSrv_MfgTmpBuf3_0:7, value-type=NvM_BlockIdType}, port=PSProxy_Rte_NvmBlock_CmnMfgSrv_MfgTmpBuf3}
        {enable-take-address=false, indirect-api=false, port-defined-argument-value{value=PSProxy_Rte_NvmBlock_CmnMfgSrv_MfgTmpBuf4_0:5, value-type=NvM_BlockIdType}, port=PSProxy_Rte_NvmBlock_CmnMfgSrv_MfgTmpBuf4}
        {enable-take-address=false, indirect-api=false, port-defined-argument-value{value=PSProxy_Rte_NvmBlock_CmnMfgSrv_NxtrMfgEnaCntr_0:43, value-type=NvM_BlockIdType}, port=PSProxy_Rte_NvmBlock_CmnMfgSrv_NxtrMfgEnaCntr}
        {enable-take-address=false, indirect-api=false, port-defined-argument-value{value=PSProxy_Rte_NvmBlock_DiagcMgr_DiagcMgrNtcFltAry_0:31, value-type=NvM_BlockIdType}, port=PSProxy_Rte_NvmBlock_DiagcMgr_DiagcMgrNtcFltAry}
        {enable-take-address=false, indirect-api=false, port-defined-argument-value{value=PSProxy_Rte_NvmBlock_DutyCycThermProtn_FilStVal_0:4, value-type=NvM_BlockIdType}, port=PSProxy_Rte_NvmBlock_DutyCycThermProtn_FilStVal}
        {enable-take-address=false, indirect-api=false, port-defined-argument-value{value=PSProxy_Rte_NvmBlock_EotLrng_EotNvmData_0:30, value-type=NvM_BlockIdType}, port=PSProxy_Rte_NvmBlock_EotLrng_EotNvmData}
        {enable-take-address=false, indirect-api=false, port-defined-argument-value{value=PSProxy_Rte_NvmBlock_HwAg0Meas_HwAg0Offs_0:41, value-type=NvM_BlockIdType}, port=PSProxy_Rte_NvmBlock_HwAg0Meas_HwAg0Offs}
        {enable-take-address=false, indirect-api=false, port-defined-argument-value{value=PSProxy_Rte_NvmBlock_HwAg1Meas_HwAg1Offs_0:39, value-type=NvM_BlockIdType}, port=PSProxy_Rte_NvmBlock_HwAg1Meas_HwAg1Offs}
        {enable-take-address=false, indirect-api=false, port-defined-argument-value{value=PSProxy_Rte_NvmBlock_HwTqCorrln_HwTqChACmnModCmpLpFilSt_0:37, value-type=NvM_BlockIdType}, port=PSProxy_Rte_NvmBlock_HwTqCorrln_HwTqChACmnModCmpLpFilSt}
        {enable-take-address=false, indirect-api=false, port-defined-argument-value{value=PSProxy_Rte_NvmBlock_HwTqCorrln_HwTqChBCmnModCmpLpFilSt_0:38, value-type=NvM_BlockIdType}, port=PSProxy_Rte_NvmBlock_HwTqCorrln_HwTqChBCmnModCmpLpFilSt}
        {enable-take-address=false, indirect-api=false, port-defined-argument-value{value=PSProxy_Rte_NvmBlock_MotAg2Meas_MtrAg2EolPrm_0:32, value-type=NvM_BlockIdType}, port=PSProxy_Rte_NvmBlock_MotAg2Meas_MtrAg2EolPrm}
        {enable-take-address=false, indirect-api=false, port-defined-argument-value{value=PSProxy_Rte_NvmBlock_NvMProxy_NvMProxyClsChkBlk_0:40, value-type=NvM_BlockIdType}, port=PSProxy_Rte_NvmBlock_NvMProxy_NvMProxyClsChkBlk}
        {enable-take-address=false, indirect-api=false, port-defined-argument-value{value=PSProxy_Rte_NvmBlock_PartNr_PartNrBasMdlPartNr_0:20, value-type=NvM_BlockIdType}, port=PSProxy_Rte_NvmBlock_PartNr_PartNrBasMdlPartNr}
        {enable-take-address=false, indirect-api=false, port-defined-argument-value{value=PSProxy_Rte_NvmBlock_PartNr_PartNrCalProgdSts_0:25, value-type=NvM_BlockIdType}, port=PSProxy_Rte_NvmBlock_PartNr_PartNrCalProgdSts}
        {enable-take-address=false, indirect-api=false, port-defined-argument-value{value=PSProxy_Rte_NvmBlock_PartNr_PartNrCcaMfgTrakg_0:16, value-type=NvM_BlockIdType}, port=PSProxy_Rte_NvmBlock_PartNr_PartNrCcaMfgTrakg}
        {enable-take-address=false, indirect-api=false, port-defined-argument-value{value=PSProxy_Rte_NvmBlock_PartNr_PartNrCtrlPidSeedKey_0:21, value-type=NvM_BlockIdType}, port=PSProxy_Rte_NvmBlock_PartNr_PartNrCtrlPidSeedKey}
        {enable-take-address=false, indirect-api=false, port-defined-argument-value{value=PSProxy_Rte_NvmBlock_PartNr_PartNrCustMfgEnaCntr_0:26, value-type=NvM_BlockIdType}, port=PSProxy_Rte_NvmBlock_PartNr_PartNrCustMfgEnaCntr}
        {enable-take-address=false, indirect-api=false, port-defined-argument-value{value=PSProxy_Rte_NvmBlock_PartNr_PartNrDataUniversalNrSysId_0:24, value-type=NvM_BlockIdType}, port=PSProxy_Rte_NvmBlock_PartNr_PartNrDataUniversalNrSysId}
        {enable-take-address=false, indirect-api=false, port-defined-argument-value{value=PSProxy_Rte_NvmBlock_PartNr_PartNrEndMdlPartNr_0:19, value-type=NvM_BlockIdType}, port=PSProxy_Rte_NvmBlock_PartNr_PartNrEndMdlPartNr}
        {enable-take-address=false, indirect-api=false, port-defined-argument-value{value=PSProxy_Rte_NvmBlock_PartNr_PartNrNxtrMfgTrakg_0:18, value-type=NvM_BlockIdType}, port=PSProxy_Rte_NvmBlock_PartNr_PartNrNxtrMfgTrakg}
        {enable-take-address=false, indirect-api=false, port-defined-argument-value{value=PSProxy_Rte_NvmBlock_PartNr_PartNrProgmDate_0:23, value-type=NvM_BlockIdType}, port=PSProxy_Rte_NvmBlock_PartNr_PartNrProgmDate}
        {enable-take-address=false, indirect-api=false, port-defined-argument-value{value=PSProxy_Rte_NvmBlock_PartNr_PartNrProgmSessionSeedKey_0:27, value-type=NvM_BlockIdType}, port=PSProxy_Rte_NvmBlock_PartNr_PartNrProgmSessionSeedKey}
        {enable-take-address=false, indirect-api=false, port-defined-argument-value{value=PSProxy_Rte_NvmBlock_PartNr_PartNrRepairShopCod_0:14, value-type=NvM_BlockIdType}, port=PSProxy_Rte_NvmBlock_PartNr_PartNrRepairShopCod}
        {enable-take-address=false, indirect-api=false, port-defined-argument-value{value=PSProxy_Rte_NvmBlock_PartNr_PartNrSysCodVersNr_0:17, value-type=NvM_BlockIdType}, port=PSProxy_Rte_NvmBlock_PartNr_PartNrSysCodVersNr}
        {enable-take-address=false, indirect-api=false, port-defined-argument-value{value=PSProxy_Rte_NvmBlock_PartNr_PartNrSysName_0:15, value-type=NvM_BlockIdType}, port=PSProxy_Rte_NvmBlock_PartNr_PartNrSysName}
        {enable-take-address=false, indirect-api=false, port-defined-argument-value{value=PSProxy_Rte_NvmBlock_PartNr_PartNrVinData_0:22, value-type=NvM_BlockIdType}, port=PSProxy_Rte_NvmBlock_PartNr_PartNrVinData}
        {enable-take-address=false, indirect-api=false, port-defined-argument-value{value=PSProxy_Rte_NvmBlock_PullCmpActv_PullCmpLongTerm_0:3, value-type=NvM_BlockIdType}, port=PSProxy_Rte_NvmBlock_PullCmpActv_PullCmpLongTerm}
      11 x runnable:
        EraseBlock: can-be-invoked-concurrently=true, symbol=NvMProxy_EraseNvBlock
        GetDataIndex: can-be-invoked-concurrently=true, symbol=NvMProxy_GetDataIndex
        GetErrorStatus: can-be-invoked-concurrently=true, symbol=NvMProxy_GetErrorStatus
        InvalidateNvBlock: can-be-invoked-concurrently=true, symbol=NvMProxy_InvalidateNvBlock
        CDD_NvMProxy_MainFunction
        ReadBlock: can-be-invoked-concurrently=true, symbol=NvMProxy_ReadBlock
        RestoreBlockDefaults: can-be-invoked-concurrently=true, symbol=NvMProxy_RestoreBlockDefaults
        SetBlockProtection: can-be-invoked-concurrently=true, symbol=NvMProxy_SetBlockProtection
        SetDataIndex: symbol=NvM_SetDataIndex
        SetRamBlockStatus: can-be-invoked-concurrently=true, symbol=NvMProxy_SetRamBlockStatus
        WriteBlock: can-be-invoked-concurrently=true, symbol=NvMProxy_WriteBlock
  swc implementation CDD_NvMProxyImplementation: behavior=CDD_NvMProxyInternalBehavior
    code-descriptors:
      code Default: artifact-descriptors=autosar-engineering-object={short-label=Default, category=SWSRC}
